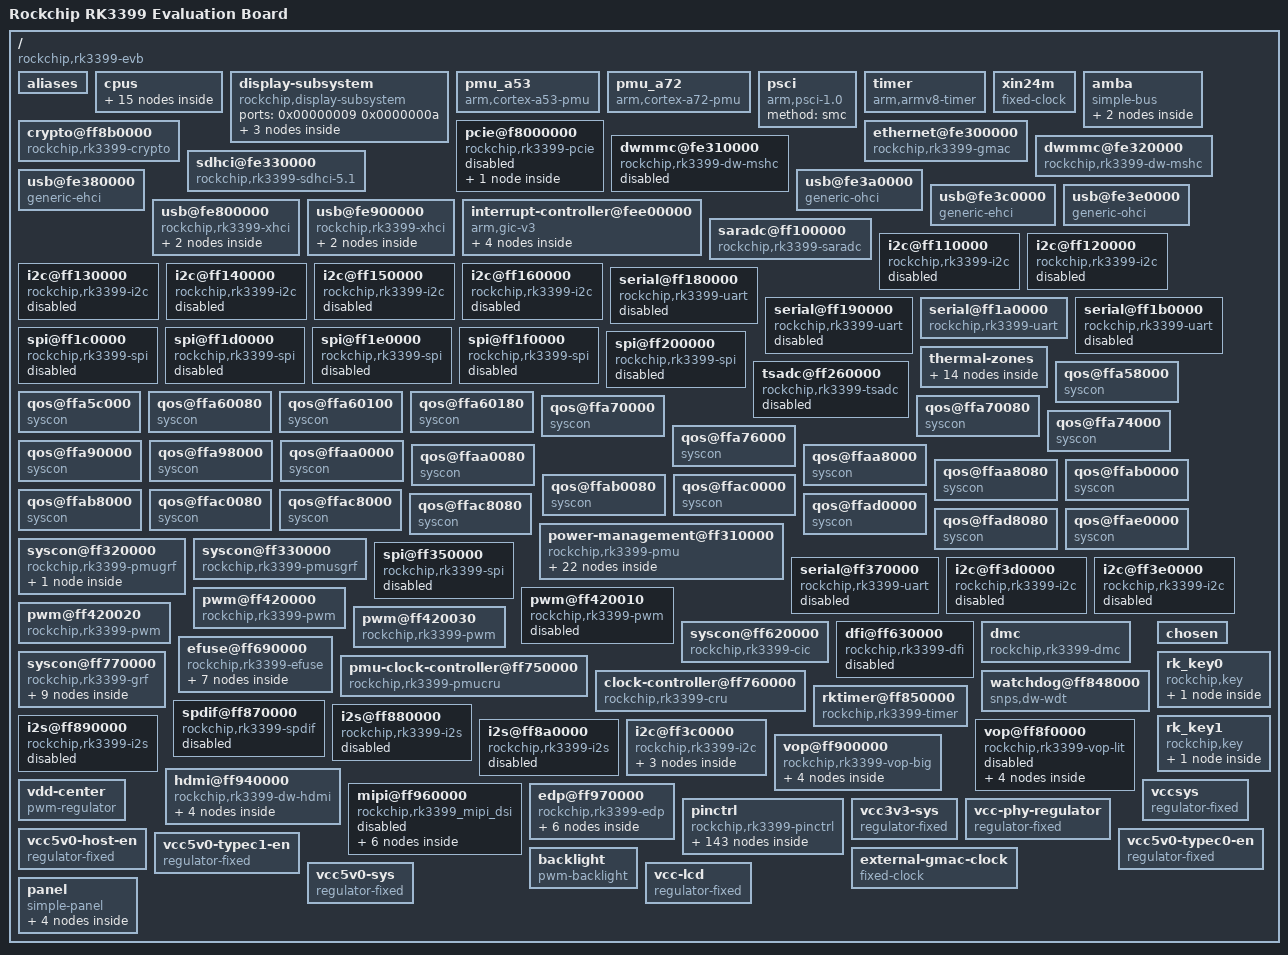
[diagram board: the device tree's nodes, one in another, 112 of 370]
/dts-v1/;
// magic:		0xd00dfeed
// totalsize:		0xc20f (49679)
// off_dt_struct:	0x38
// off_dt_strings:	0xb968
// off_mem_rsvmap:	0x28
// version:		17
// last_comp_version:	16
// boot_cpuid_phys:	0x0
// size_dt_strings:	0x8a7
// size_dt_struct:	0xb930

/ {
    compatible = "rockchip,rk3399-evb", "rockchip,rk3399", "google,rk3399evb-rev2";
    interrupt-parent = <0x00000001>;
    #address-cells = <0x00000002>;
    #size-cells = <0x00000002>;
    model = "Rockchip RK3399 Evaluation Board";
    aliases {
        i2c0 = "/i2c@ff3c0000";
        i2c1 = "/i2c@ff110000";
        i2c2 = "/i2c@ff120000";
        i2c3 = "/i2c@ff130000";
        i2c4 = "/i2c@ff3d0000";
        i2c5 = "/i2c@ff140000";
        i2c6 = "/i2c@ff150000";
        i2c7 = "/i2c@ff160000";
        i2c8 = "/i2c@ff3e0000";
        serial0 = "/serial@ff180000";
        serial1 = "/serial@ff190000";
        serial2 = "/serial@ff1a0000";
        serial3 = "/serial@ff1b0000";
        serial4 = "/serial@ff370000";
        mmc0 = "/sdhci@fe330000";
        mmc1 = "/dwmmc@fe320000";
    };
    cpus {
        #address-cells = <0x00000002>;
        #size-cells = <0x00000000>;
        cpu-map {
            cluster0 {
                core0 {
                    cpu = <0x00000002>;
                };
                core1 {
                    cpu = <0x00000003>;
                };
                core2 {
                    cpu = <0x00000004>;
                };
                core3 {
                    cpu = <0x00000005>;
                };
            };
            cluster1 {
                core0 {
                    cpu = <0x00000006>;
                };
                core1 {
                    cpu = <0x00000007>;
                };
            };
        };
        cpu@0 {
            device_type = "cpu";
            compatible = "arm,cortex-a53", "arm,armv8";
            reg = <0x00000000 0x00000000>;
            enable-method = "psci";
            #cooling-cells = <0x00000002>;
            clocks = <0x00000008 0x00000008>;
            phandle = <0x00000002>;
        };
        cpu@1 {
            device_type = "cpu";
            compatible = "arm,cortex-a53", "arm,armv8";
            reg = <0x00000000 0x00000001>;
            enable-method = "psci";
            clocks = <0x00000008 0x00000008>;
            phandle = <0x00000003>;
        };
        cpu@2 {
            device_type = "cpu";
            compatible = "arm,cortex-a53", "arm,armv8";
            reg = <0x00000000 0x00000002>;
            enable-method = "psci";
            clocks = <0x00000008 0x00000008>;
            phandle = <0x00000004>;
        };
        cpu@3 {
            device_type = "cpu";
            compatible = "arm,cortex-a53", "arm,armv8";
            reg = <0x00000000 0x00000003>;
            enable-method = "psci";
            clocks = <0x00000008 0x00000008>;
            phandle = <0x00000005>;
        };
        cpu@100 {
            device_type = "cpu";
            compatible = "arm,cortex-a72", "arm,armv8";
            reg = <0x00000000 0x00000100>;
            enable-method = "psci";
            #cooling-cells = <0x00000002>;
            clocks = <0x00000008 0x00000009>;
            phandle = <0x00000006>;
        };
        cpu@101 {
            device_type = "cpu";
            compatible = "arm,cortex-a72", "arm,armv8";
            reg = <0x00000000 0x00000101>;
            enable-method = "psci";
            clocks = <0x00000008 0x00000009>;
            phandle = <0x00000007>;
        };
    };
    display-subsystem {
        compatible = "rockchip,display-subsystem";
        ports = <0x00000009 0x0000000a>;
        status = "okay";
        route {
            route-hdmi {
                status = "disabled";
                logo,uboot = "logo.bmp";
                logo,kernel = "logo_kernel.bmp";
                logo,mode = "center";
                charge_logo,mode = "center";
                connect = <0x0000000b>;
            };
            route-edp {
                status = "okay";
                logo,uboot = "logo.bmp";
                logo,kernel = "logo_kernel.bmp";
                logo,mode = "center";
                charge_logo,mode = "center";
                connect = <0x0000000c>;
            };
        };
    };
    pmu_a53 {
        compatible = "arm,cortex-a53-pmu";
        interrupts = <0x00000001 0x00000007 0x00000008 0x0000000d>;
    };
    pmu_a72 {
        compatible = "arm,cortex-a72-pmu";
        interrupts = <0x00000001 0x00000007 0x00000008 0x0000000e>;
    };
    psci {
        compatible = "arm,psci-1.0";
        method = "smc";
    };
    timer {
        compatible = "arm,armv8-timer";
        interrupts = <0x00000001 0x0000000d 0x00000008 0x00000000 0x00000001 0x0000000e 0x00000008 0x00000000 0x00000001 0x0000000b 0x00000008 0x00000000 0x00000001 0x0000000a 0x00000008 0x00000000>;
        arm,no-tick-in-suspend;
    };
    xin24m {
        compatible = "fixed-clock";
        clock-frequency = <0x016e3600>;
        clock-output-names = "xin24m";
        #clock-cells = <0x00000000>;
    };
    amba {
        compatible = "simple-bus";
        #address-cells = <0x00000002>;
        #size-cells = <0x00000002>;
        ranges;
        dma-controller@ff6d0000 {
            compatible = "arm,pl330", "arm,primecell";
            reg = <0x00000000 0xff6d0000 0x00000000 0x00004000>;
            interrupts = <0x00000000 0x00000005 0x00000004 0x00000000 0x00000000 0x00000006 0x00000004 0x00000000>;
            #dma-cells = <0x00000001>;
            clocks = <0x00000008 0x000000d3>;
            clock-names = "apb_pclk";
            phandle = <0x0000006b>;
        };
        dma-controller@ff6e0000 {
            compatible = "arm,pl330", "arm,primecell";
            reg = <0x00000000 0xff6e0000 0x00000000 0x00004000>;
            interrupts = <0x00000000 0x00000007 0x00000004 0x00000000 0x00000000 0x00000008 0x00000004 0x00000000>;
            #dma-cells = <0x00000001>;
            clocks = <0x00000008 0x000000d4>;
            clock-names = "apb_pclk";
        };
    };
    crypto@ff8b0000 {
        compatible = "rockchip,rk3399-crypto";
        reg = <0x00000000 0xff8b0000 0x00000000 0x00010000>;
        clock-names = "sclk_crypto0";
        clocks = <0x00000008 0x00000085 0x00000008 0x00000086>;
        status = "okay";
        u-boot,dm-pre-reloc;
    };
    pcie@f8000000 {
        compatible = "rockchip,rk3399-pcie";
        reg = <0x00000000 0xf8000000 0x00000000 0x02000000 0x00000000 0xfd000000 0x00000000 0x01000000>;
        reg-names = "axi-base", "apb-base";
        #address-cells = <0x00000003>;
        #size-cells = <0x00000002>;
        #interrupt-cells = <0x00000001>;
        aspm-no-l0s;
        bus-range = <0x00000000 0x00000001>;
        clocks = <0x00000008 0x000000c5 0x00000008 0x000000c4 0x00000008 0x00000147 0x00000008 0x000000a0>;
        clock-names = "aclk", "aclk-perf", "hclk", "pm";
        interrupts = <0x00000000 0x00000031 0x00000004 0x00000000 0x00000000 0x00000032 0x00000004 0x00000000 0x00000000 0x00000033 0x00000004 0x00000000>;
        interrupt-names = "sys", "legacy", "client";
        interrupt-map-mask = <0x00000000 0x00000000 0x00000000 0x00000007>;
        interrupt-map = <0x00000000 0x00000000 0x00000000 0x00000001 0x0000000f 0x00000000 0x00000000 0x00000000 0x00000000 0x00000002 0x0000000f 0x00000001 0x00000000 0x00000000 0x00000000 0x00000003 0x0000000f 0x00000002 0x00000000 0x00000000 0x00000000 0x00000004 0x0000000f 0x00000003>;
        linux,pci-domain = <0x00000000>;
        max-link-speed = <0x00000001>;
        msi-map = <0x00000000 0x00000010 0x00000000 0x00001000>;
        phys = <0x00000011>;
        phy-names = "pcie-phy";
        ranges = <0x83000000 0x00000000 0xfa000000 0x00000000 0xfa000000 0x00000000 0x00600000 0x81000000 0x00000000 0xfa600000 0x00000000 0xfa600000 0x00000000 0x00100000>;
        resets = <0x00000008 0x00000082 0x00000008 0x00000083 0x00000008 0x00000084 0x00000008 0x00000085 0x00000008 0x00000086 0x00000008 0x00000081 0x00000008 0x00000080>;
        reset-names = "core", "mgmt", "mgmt-sticky", "pipe", "pm", "pclk", "aclk";
        status = "disabled";
        interrupt-controller {
            interrupt-controller;
            #address-cells = <0x00000000>;
            #interrupt-cells = <0x00000001>;
            phandle = <0x0000000f>;
        };
    };
    ethernet@fe300000 {
        compatible = "rockchip,rk3399-gmac";
        reg = <0x00000000 0xfe300000 0x00000000 0x00010000>;
        interrupts = <0x00000000 0x0000000c 0x00000004 0x00000000>;
        interrupt-names = "macirq";
        clocks = <0x00000008 0x00000069 0x00000008 0x00000067 0x00000008 0x00000068 0x00000008 0x00000066 0x00000008 0x0000006a 0x00000008 0x000000d5 0x00000008 0x00000166>;
        clock-names = "stmmaceth", "mac_clk_rx", "mac_clk_tx", "clk_mac_ref", "clk_mac_refout", "aclk_mac", "pclk_mac";
        power-domains = <0x00000012 0x00000016>;
        resets = <0x00000008 0x00000089>;
        reset-names = "stmmaceth";
        rockchip,grf = <0x00000013>;
        status = "okay";
        phy-supply = <0x00000014>;
        phy-mode = "rgmii";
        clock_in_out = "input";
        snps,reset-gpio = <0x00000015 0x0000000f 0x00000001>;
        snps,reset-active-low;
        snps,reset-delays-us = <0x00000000 0x00002710 0x0000c350>;
        assigned-clocks = <0x00000008 0x000000a6>;
        assigned-clock-parents = <0x00000016>;
        pinctrl-names = "default";
        pinctrl-0 = <0x00000017>;
        tx_delay = <0x00000028>;
        rx_delay = <0x00000011>;
    };
    dwmmc@fe310000 {
        compatible = "rockchip,rk3399-dw-mshc", "rockchip,rk3288-dw-mshc";
        reg = <0x00000000 0xfe310000 0x00000000 0x00004000>;
        interrupts = <0x00000000 0x00000040 0x00000004 0x00000000>;
        max-frequency = <0x08f0d180>;
        clocks = <0x00000008 0x000001ee 0x00000008 0x0000004d 0x00000008 0x0000009c 0x00000008 0x0000009d>;
        clock-names = "biu", "ciu", "ciu-drive", "ciu-sample";
        fifo-depth = <0x00000100>;
        power-domains = <0x00000012 0x0000001c>;
        resets = <0x00000008 0x00000079>;
        reset-names = "reset";
        status = "disabled";
    };
    dwmmc@fe320000 {
        compatible = "rockchip,rk3399-dw-mshc", "rockchip,rk3288-dw-mshc";
        reg = <0x00000000 0xfe320000 0x00000000 0x00004000>;
        interrupts = <0x00000000 0x00000041 0x00000004 0x00000000>;
        max-frequency = <0x08f0d180>;
        clocks = <0x00000008 0x000001ce 0x00000008 0x0000004c 0x00000008 0x0000009a 0x00000008 0x0000009b>;
        clock-names = "biu", "ciu", "ciu-drive", "ciu-sample";
        fifo-depth = <0x00000100>;
        power-domains = <0x00000012 0x0000001b>;
        resets = <0x00000008 0x0000007a>;
        reset-names = "reset";
        status = "okay";
        u-boot,dm-pre-reloc;
        bus-width = <0x00000004>;
    };
    sdhci@fe330000 {
        compatible = "rockchip,rk3399-sdhci-5.1", "arasan,sdhci-5.1";
        reg = <0x00000000 0xfe330000 0x00000000 0x00010000>;
        interrupts = <0x00000000 0x0000000b 0x00000004 0x00000000>;
        arasan,soc-ctl-syscon = <0x00000013>;
        assigned-clocks = <0x00000008 0x0000004e>;
        assigned-clock-rates = <0x0bebc200>;
        max-frequency = <0x08f0d180>;
        clocks = <0x00000008 0x0000004e 0x00000008 0x000000f0>;
        clock-names = "clk_xin", "clk_ahb";
        clock-output-names = "emmc_cardclock";
        #clock-cells = <0x00000000>;
        phys = <0x00000018>;
        phy-names = "phy_arasan";
        power-domains = <0x00000012 0x00000017>;
        status = "okay";
        u-boot,dm-pre-reloc;
        bus-width = <0x00000008>;
        mmc-hs400-1_8v;
        mmc-hs400-enhanced-strobe;
        non-removable;
        phandle = <0x0000006a>;
    };
    usb@fe380000 {
        compatible = "generic-ehci";
        reg = <0x00000000 0xfe380000 0x00000000 0x00020000>;
        interrupts = <0x00000000 0x0000001a 0x00000004 0x00000000>;
        clocks = <0x00000008 0x000001c8 0x00000008 0x000001c9 0x00000019>;
        clock-names = "usbhost", "arbiter", "utmi";
        phys = <0x0000001a>;
        phy-names = "usb";
        power-domains = <0x00000012 0x0000000e>;
        status = "okay";
    };
    usb@fe3a0000 {
        compatible = "generic-ohci";
        reg = <0x00000000 0xfe3a0000 0x00000000 0x00020000>;
        interrupts = <0x00000000 0x0000001c 0x00000004 0x00000000>;
        clocks = <0x00000008 0x000001c8 0x00000008 0x000001c9 0x00000019>;
        clock-names = "usbhost", "arbiter", "utmi";
        phys = <0x0000001a>;
        phy-names = "usb";
        power-domains = <0x00000012 0x0000000e>;
        status = "okay";
    };
    usb@fe3c0000 {
        compatible = "generic-ehci";
        reg = <0x00000000 0xfe3c0000 0x00000000 0x00020000>;
        interrupts = <0x00000000 0x0000001e 0x00000004 0x00000000>;
        clocks = <0x00000008 0x000001ca 0x00000008 0x000001cb 0x0000001b>;
        clock-names = "usbhost", "arbiter", "utmi";
        phys = <0x0000001c>;
        phy-names = "usb";
        power-domains = <0x00000012 0x0000000e>;
        status = "okay";
    };
    usb@fe3e0000 {
        compatible = "generic-ohci";
        reg = <0x00000000 0xfe3e0000 0x00000000 0x00020000>;
        interrupts = <0x00000000 0x00000020 0x00000004 0x00000000>;
        clocks = <0x00000008 0x000001ca 0x00000008 0x000001cb 0x0000001b>;
        clock-names = "usbhost", "arbiter", "utmi";
        phys = <0x0000001c>;
        phy-names = "usb";
        power-domains = <0x00000012 0x0000000e>;
        status = "okay";
    };
    usb@fe800000 {
        compatible = "rockchip,rk3399-xhci";
        reg = <0x00000000 0xfe800000 0x00000000 0x00100000>;
        status = "okay";
        snps,dis-enblslpm-quirk;
        snps,phyif-utmi-bits = <0x00000010>;
        snps,dis-u2-freeclk-exists-quirk;
        snps,dis-u2-susphy-quirk;
        #address-cells = <0x00000002>;
        #size-cells = <0x00000002>;
        u-boot,dm-pre-reloc;
        vbus-supply = <0x0000001d>;
        hub {
            compatible = "usb-hub";
            usb,device-class = <0x00000009>;
        };
        typec_phy0 {
            compatible = "rockchip,rk3399-usb3-phy";
            reg = <0x00000000 0xff7c0000 0x00000000 0x00040000>;
        };
    };
    usb@fe900000 {
        compatible = "rockchip,rk3399-xhci";
        reg = <0x00000000 0xfe900000 0x00000000 0x00100000>;
        status = "okay";
        snps,dis-enblslpm-quirk;
        snps,phyif-utmi-bits = <0x00000010>;
        snps,dis-u2-freeclk-exists-quirk;
        snps,dis-u2-susphy-quirk;
        #address-cells = <0x00000002>;
        #size-cells = <0x00000002>;
        u-boot,dm-pre-reloc;
        vbus-supply = <0x0000001e>;
        hub {
            compatible = "usb-hub";
            usb,device-class = <0x00000009>;
        };
        typec_phy1 {
            compatible = "rockchip,rk3399-usb3-phy";
            reg = <0x00000000 0xff800000 0x00000000 0x00040000>;
        };
    };
    interrupt-controller@fee00000 {
        compatible = "arm,gic-v3";
        #interrupt-cells = <0x00000004>;
        #address-cells = <0x00000002>;
        #size-cells = <0x00000002>;
        ranges;
        interrupt-controller;
        reg = <0x00000000 0xfee00000 0x00000000 0x00010000 0x00000000 0xfef00000 0x00000000 0x000c0000 0x00000000 0xfff00000 0x00000000 0x00010000 0x00000000 0xfff10000 0x00000000 0x00010000 0x00000000 0xfff20000 0x00000000 0x00010000>;
        interrupts = <0x00000001 0x00000009 0x00000004 0x00000000>;
        phandle = <0x00000001>;
        interrupt-controller@fee20000 {
            compatible = "arm,gic-v3-its";
            msi-controller;
            reg = <0x00000000 0xfee20000 0x00000000 0x00020000>;
            phandle = <0x00000010>;
        };
        ppi-partitions {
            interrupt-partition-0 {
                affinity = <0x00000002 0x00000003 0x00000004 0x00000005>;
                phandle = <0x0000000d>;
            };
            interrupt-partition-1 {
                affinity = <0x00000006 0x00000007>;
                phandle = <0x0000000e>;
            };
        };
    };
    saradc@ff100000 {
        compatible = "rockchip,rk3399-saradc";
        reg = <0x00000000 0xff100000 0x00000000 0x00000100>;
        interrupts = <0x00000000 0x0000003e 0x00000004 0x00000000>;
        #io-channel-cells = <0x00000001>;
        clocks = <0x00000008 0x00000050 0x00000008 0x00000165>;
        clock-names = "saradc", "apb_pclk";
        resets = <0x00000008 0x000000d4>;
        reset-names = "saradc-apb";
        status = "okay";
        u-boot,dm-pre-reloc;
        phandle = <0x00000086>;
    };
    i2c@ff110000 {
        compatible = "rockchip,rk3399-i2c";
        reg = <0x00000000 0xff110000 0x00000000 0x00001000>;
        assigned-clocks = <0x00000008 0x00000041>;
        assigned-clock-rates = <0x0bebc200>;
        clocks = <0x00000008 0x00000041 0x00000008 0x00000155>;
        clock-names = "i2c", "pclk";
        interrupts = <0x00000000 0x0000003b 0x00000004 0x00000000>;
        pinctrl-names = "default";
        pinctrl-0 = <0x0000001f>;
        #address-cells = <0x00000001>;
        #size-cells = <0x00000000>;
        status = "disabled";
    };
    i2c@ff120000 {
        compatible = "rockchip,rk3399-i2c";
        reg = <0x00000000 0xff120000 0x00000000 0x00001000>;
        assigned-clocks = <0x00000008 0x00000042>;
        assigned-clock-rates = <0x0bebc200>;
        clocks = <0x00000008 0x00000042 0x00000008 0x00000156>;
        clock-names = "i2c", "pclk";
        interrupts = <0x00000000 0x00000023 0x00000004 0x00000000>;
        pinctrl-names = "default";
        pinctrl-0 = <0x00000020>;
        #address-cells = <0x00000001>;
        #size-cells = <0x00000000>;
        status = "disabled";
    };
    i2c@ff130000 {
        compatible = "rockchip,rk3399-i2c";
        reg = <0x00000000 0xff130000 0x00000000 0x00001000>;
        assigned-clocks = <0x00000008 0x00000043>;
        assigned-clock-rates = <0x0bebc200>;
        clocks = <0x00000008 0x00000043 0x00000008 0x00000157>;
        clock-names = "i2c", "pclk";
        interrupts = <0x00000000 0x00000022 0x00000004 0x00000000>;
        pinctrl-names = "default";
        pinctrl-0 = <0x00000021>;
        #address-cells = <0x00000001>;
        #size-cells = <0x00000000>;
        status = "disabled";
    };
    i2c@ff140000 {
        compatible = "rockchip,rk3399-i2c";
        reg = <0x00000000 0xff140000 0x00000000 0x00001000>;
        assigned-clocks = <0x00000008 0x00000044>;
        assigned-clock-rates = <0x0bebc200>;
        clocks = <0x00000008 0x00000044 0x00000008 0x00000158>;
        clock-names = "i2c", "pclk";
        interrupts = <0x00000000 0x00000026 0x00000004 0x00000000>;
        pinctrl-names = "default";
        pinctrl-0 = <0x00000022>;
        #address-cells = <0x00000001>;
        #size-cells = <0x00000000>;
        status = "disabled";
    };
    i2c@ff150000 {
        compatible = "rockchip,rk3399-i2c";
        reg = <0x00000000 0xff150000 0x00000000 0x00001000>;
        assigned-clocks = <0x00000008 0x00000045>;
        assigned-clock-rates = <0x0bebc200>;
        clocks = <0x00000008 0x00000045 0x00000008 0x00000159>;
        clock-names = "i2c", "pclk";
        interrupts = <0x00000000 0x00000025 0x00000004 0x00000000>;
        pinctrl-names = "default";
        pinctrl-0 = <0x00000023>;
        #address-cells = <0x00000001>;
        #size-cells = <0x00000000>;
        status = "disabled";
    };
    i2c@ff160000 {
        compatible = "rockchip,rk3399-i2c";
        reg = <0x00000000 0xff160000 0x00000000 0x00001000>;
        assigned-clocks = <0x00000008 0x00000046>;
        assigned-clock-rates = <0x0bebc200>;
        clocks = <0x00000008 0x00000046 0x00000008 0x0000015a>;
        clock-names = "i2c", "pclk";
        interrupts = <0x00000000 0x00000024 0x00000004 0x00000000>;
        pinctrl-names = "default";
        pinctrl-0 = <0x00000024>;
        #address-cells = <0x00000001>;
        #size-cells = <0x00000000>;
        status = "disabled";
    };
    serial@ff180000 {
        compatible = "rockchip,rk3399-uart", "snps,dw-apb-uart";
        reg = <0x00000000 0xff180000 0x00000000 0x00000100>;
        clocks = <0x00000008 0x00000051 0x00000008 0x00000160>;
        clock-names = "baudclk", "apb_pclk";
        interrupts = <0x00000000 0x00000063 0x00000004 0x00000000>;
        reg-shift = <0x00000002>;
        reg-io-width = <0x00000004>;
        pinctrl-names = "default";
        pinctrl-0 = <0x00000025>;
        status = "disabled";
    };
    serial@ff190000 {
        compatible = "rockchip,rk3399-uart", "snps,dw-apb-uart";
        reg = <0x00000000 0xff190000 0x00000000 0x00000100>;
        clocks = <0x00000008 0x00000052 0x00000008 0x00000161>;
        clock-names = "baudclk", "apb_pclk";
        interrupts = <0x00000000 0x00000062 0x00000004 0x00000000>;
        reg-shift = <0x00000002>;
        reg-io-width = <0x00000004>;
        pinctrl-names = "default";
        pinctrl-0 = <0x00000026>;
        status = "disabled";
    };
    serial@ff1a0000 {
        compatible = "rockchip,rk3399-uart", "snps,dw-apb-uart";
        reg = <0x00000000 0xff1a0000 0x00000000 0x00000100>;
        clocks = <0x00000008 0x00000053 0x00000008 0x00000162>;
        clock-names = "baudclk", "apb_pclk";
        interrupts = <0x00000000 0x00000064 0x00000004 0x00000000>;
        clock-frequency = <0x016e3600>;
        reg-shift = <0x00000002>;
        reg-io-width = <0x00000004>;
        pinctrl-names = "default";
        pinctrl-0 = <0x00000027>;
        status = "okay";
        u-boot,dm-pre-reloc;
    };
    serial@ff1b0000 {
        compatible = "rockchip,rk3399-uart", "snps,dw-apb-uart";
        reg = <0x00000000 0xff1b0000 0x00000000 0x00000100>;
        clocks = <0x00000008 0x00000054 0x00000008 0x00000163>;
        clock-names = "baudclk", "apb_pclk";
        interrupts = <0x00000000 0x00000065 0x00000004 0x00000000>;
        reg-shift = <0x00000002>;
        reg-io-width = <0x00000004>;
        pinctrl-names = "default";
        pinctrl-0 = <0x00000028>;
        status = "disabled";
    };
    spi@ff1c0000 {
        compatible = "rockchip,rk3399-spi", "rockchip,rk3066-spi";
        reg = <0x00000000 0xff1c0000 0x00000000 0x00001000>;
        clocks = <0x00000008 0x00000047 0x00000008 0x0000015b>;
        clock-names = "spiclk", "apb_pclk";
        interrupts = <0x00000000 0x00000044 0x00000004 0x00000000>;
        pinctrl-names = "default";
        pinctrl-0 = <0x00000029 0x0000002a 0x0000002b 0x0000002c>;
        #address-cells = <0x00000001>;
        #size-cells = <0x00000000>;
        status = "disabled";
    };
    spi@ff1d0000 {
        compatible = "rockchip,rk3399-spi", "rockchip,rk3066-spi";
        reg = <0x00000000 0xff1d0000 0x00000000 0x00001000>;
        clocks = <0x00000008 0x00000048 0x00000008 0x0000015c>;
        clock-names = "spiclk", "apb_pclk";
        interrupts = <0x00000000 0x00000035 0x00000004 0x00000000>;
        pinctrl-names = "default";
        pinctrl-0 = <0x0000002d 0x0000002e 0x0000002f 0x00000030>;
        #address-cells = <0x00000001>;
        #size-cells = <0x00000000>;
        status = "disabled";
    };
    spi@ff1e0000 {
        compatible = "rockchip,rk3399-spi", "rockchip,rk3066-spi";
        reg = <0x00000000 0xff1e0000 0x00000000 0x00001000>;
        clocks = <0x00000008 0x00000049 0x00000008 0x0000015d>;
        clock-names = "spiclk", "apb_pclk";
        interrupts = <0x00000000 0x00000034 0x00000004 0x00000000>;
        pinctrl-names = "default";
        pinctrl-0 = <0x00000031 0x00000032 0x00000033 0x00000034>;
        #address-cells = <0x00000001>;
        #size-cells = <0x00000000>;
        status = "disabled";
    };
    spi@ff1f0000 {
        compatible = "rockchip,rk3399-spi", "rockchip,rk3066-spi";
        reg = <0x00000000 0xff1f0000 0x00000000 0x00001000>;
        clocks = <0x00000008 0x0000004a 0x00000008 0x0000015e>;
        clock-names = "spiclk", "apb_pclk";
        interrupts = <0x00000000 0x00000043 0x00000004 0x00000000>;
        pinctrl-names = "default";
        pinctrl-0 = <0x00000035 0x00000036 0x00000037 0x00000038>;
        #address-cells = <0x00000001>;
        #size-cells = <0x00000000>;
        status = "disabled";
    };
    spi@ff200000 {
        compatible = "rockchip,rk3399-spi", "rockchip,rk3066-spi";
        reg = <0x00000000 0xff200000 0x00000000 0x00001000>;
        clocks = <0x00000008 0x0000004b 0x00000008 0x0000015f>;
        clock-names = "spiclk", "apb_pclk";
        interrupts = <0x00000000 0x00000084 0x00000004 0x00000000>;
        pinctrl-names = "default";
        pinctrl-0 = <0x00000039 0x0000003a 0x0000003b 0x0000003c>;
        #address-cells = <0x00000001>;
        #size-cells = <0x00000000>;
        status = "disabled";
    };
    thermal-zones {
        cpu {
            polling-delay-passive = <0x00000064>;
            polling-delay = <0x000003e8>;
            thermal-sensors = <0x0000003d 0x00000000>;
            trips {
                cpu_alert0 {
                    temperature = <0x00011170>;
                    hysteresis = <0x000007d0>;
                    type = "passive";
                    phandle = <0x0000003e>;
                };
                cpu_alert1 {
                    temperature = <0x000124f8>;
                    hysteresis = <0x000007d0>;
                    type = "passive";
                    phandle = <0x0000003f>;
                };
                cpu_crit {
                    temperature = <0x00017318>;
                    hysteresis = <0x000007d0>;
                    type = "critical";
                };
            };
            cooling-maps {
                map0 {
                    trip = <0x0000003e>;
                    cooling-device = <0x00000006 0xffffffff 0xffffffff>;
                };
                map1 {
                    trip = <0x0000003f>;
                    cooling-device = <0x00000002 0xffffffff 0xffffffff 0x00000006 0xffffffff 0xffffffff>;
                };
            };
        };
        gpu {
            polling-delay-passive = <0x00000064>;
            polling-delay = <0x000003e8>;
            thermal-sensors = <0x0000003d 0x00000001>;
            trips {
                gpu_alert0 {
                    temperature = <0x000124f8>;
                    hysteresis = <0x000007d0>;
                    type = "passive";
                    phandle = <0x00000040>;
                };
                gpu_crit {
                    temperature = <0x00017318>;
                    hysteresis = <0x000007d0>;
                    type = "critical";
                };
            };
            cooling-maps {
                map0 {
                    trip = <0x00000040>;
                    cooling-device = <0x00000006 0xffffffff 0xffffffff>;
                };
            };
        };
    };
    tsadc@ff260000 {
        compatible = "rockchip,rk3399-tsadc";
        reg = <0x00000000 0xff260000 0x00000000 0x00000100>;
        interrupts = <0x00000000 0x00000061 0x00000004 0x00000000>;
        assigned-clocks = <0x00000008 0x0000004f>;
        assigned-clock-rates = <0x000b71b0>;
        clocks = <0x00000008 0x0000004f 0x00000008 0x00000164>;
        clock-names = "tsadc", "apb_pclk";
        resets = <0x00000008 0x000000e8>;
        reset-names = "tsadc-apb";
        rockchip,grf = <0x00000013>;
        rockchip,hw-tshut-temp = <0x00017318>;
        pinctrl-names = "init", "default", "sleep";
        pinctrl-0 = <0x00000041>;
        pinctrl-1 = <0x00000042>;
        pinctrl-2 = <0x00000041>;
        #thermal-sensor-cells = <0x00000001>;
        status = "disabled";
        phandle = <0x0000003d>;
    };
    qos@ffa58000 {
        compatible = "syscon";
        reg = <0x00000000 0xffa58000 0x00000000 0x00000020>;
        phandle = <0x0000004a>;
    };
    qos@ffa5c000 {
        compatible = "syscon";
        reg = <0x00000000 0xffa5c000 0x00000000 0x00000020>;
        phandle = <0x0000004b>;
    };
    qos@ffa60080 {
        compatible = "syscon";
        reg = <0x00000000 0xffa60080 0x00000000 0x00000020>;
        phandle = <0x0000004d>;
    };
    qos@ffa60100 {
        compatible = "syscon";
        reg = <0x00000000 0xffa60100 0x00000000 0x00000020>;
        phandle = <0x0000004e>;
    };
    qos@ffa60180 {
        compatible = "syscon";
        reg = <0x00000000 0xffa60180 0x00000000 0x00000020>;
        phandle = <0x0000004f>;
    };
    qos@ffa70000 {
        compatible = "syscon";
        reg = <0x00000000 0xffa70000 0x00000000 0x00000020>;
        phandle = <0x00000052>;
    };
    qos@ffa70080 {
        compatible = "syscon";
        reg = <0x00000000 0xffa70080 0x00000000 0x00000020>;
        phandle = <0x00000053>;
    };
    qos@ffa74000 {
        compatible = "syscon";
        reg = <0x00000000 0xffa74000 0x00000000 0x00000020>;
        phandle = <0x00000050>;
    };
    qos@ffa76000 {
        compatible = "syscon";
        reg = <0x00000000 0xffa76000 0x00000000 0x00000020>;
        phandle = <0x00000051>;
    };
    qos@ffa90000 {
        compatible = "syscon";
        reg = <0x00000000 0xffa90000 0x00000000 0x00000020>;
        phandle = <0x00000054>;
    };
    qos@ffa98000 {
        compatible = "syscon";
        reg = <0x00000000 0xffa98000 0x00000000 0x00000020>;
        phandle = <0x00000043>;
    };
    qos@ffaa0000 {
        compatible = "syscon";
        reg = <0x00000000 0xffaa0000 0x00000000 0x00000020>;
        phandle = <0x00000055>;
    };
    qos@ffaa0080 {
        compatible = "syscon";
        reg = <0x00000000 0xffaa0080 0x00000000 0x00000020>;
        phandle = <0x00000056>;
    };
    qos@ffaa8000 {
        compatible = "syscon";
        reg = <0x00000000 0xffaa8000 0x00000000 0x00000020>;
        phandle = <0x00000057>;
    };
    qos@ffaa8080 {
        compatible = "syscon";
        reg = <0x00000000 0xffaa8080 0x00000000 0x00000020>;
        phandle = <0x00000058>;
    };
    qos@ffab0000 {
        compatible = "syscon";
        reg = <0x00000000 0xffab0000 0x00000000 0x00000020>;
        phandle = <0x00000044>;
    };
    qos@ffab0080 {
        compatible = "syscon";
        reg = <0x00000000 0xffab0080 0x00000000 0x00000020>;
        phandle = <0x00000045>;
    };
    qos@ffab8000 {
        compatible = "syscon";
        reg = <0x00000000 0xffab8000 0x00000000 0x00000020>;
        phandle = <0x00000046>;
    };
    qos@ffac0000 {
        compatible = "syscon";
        reg = <0x00000000 0xffac0000 0x00000000 0x00000020>;
        phandle = <0x00000047>;
    };
    qos@ffac0080 {
        compatible = "syscon";
        reg = <0x00000000 0xffac0080 0x00000000 0x00000020>;
        phandle = <0x00000048>;
    };
    qos@ffac8000 {
        compatible = "syscon";
        reg = <0x00000000 0xffac8000 0x00000000 0x00000020>;
        phandle = <0x00000059>;
    };
    qos@ffac8080 {
        compatible = "syscon";
        reg = <0x00000000 0xffac8080 0x00000000 0x00000020>;
        phandle = <0x0000005a>;
    };
    qos@ffad0000 {
        compatible = "syscon";
        reg = <0x00000000 0xffad0000 0x00000000 0x00000020>;
        phandle = <0x0000005b>;
    };
    qos@ffad8080 {
        compatible = "syscon";
        reg = <0x00000000 0xffad8080 0x00000000 0x00000020>;
        phandle = <0x0000004c>;
    };
    qos@ffae0000 {
        compatible = "syscon";
        reg = <0x00000000 0xffae0000 0x00000000 0x00000020>;
        phandle = <0x00000049>;
    };
    power-management@ff310000 {
        compatible = "rockchip,rk3399-pmu", "syscon", "simple-mfd";
        reg = <0x00000000 0xff310000 0x00000000 0x00001000>;
        u-boot,dm-pre-reloc;
        power-controller {
            compatible = "rockchip,rk3399-power-controller";
            #power-domain-cells = <0x00000001>;
            #address-cells = <0x00000001>;
            #size-cells = <0x00000000>;
            phandle = <0x00000012>;
            pd_iep@34 {
                reg = <0x00000022>;
                clocks = <0x00000008 0x000000e1 0x00000008 0x000001dd>;
                pm_qos = <0x00000043>;
            };
            pd_rga@33 {
                reg = <0x00000021>;
                clocks = <0x00000008 0x000000dc 0x00000008 0x000001e5>;
                pm_qos = <0x00000044 0x00000045>;
            };
            pd_vcodec@31 {
                reg = <0x0000001f>;
                clocks = <0x00000008 0x000000eb 0x00000008 0x000001ea>;
                pm_qos = <0x00000046>;
            };
            pd_vdu@32 {
                reg = <0x00000020>;
                clocks = <0x00000008 0x000000ed 0x00000008 0x000001ec>;
                pm_qos = <0x00000047 0x00000048>;
            };
            pd_gpu@35 {
                reg = <0x00000023>;
                clocks = <0x00000008 0x000000d0>;
                pm_qos = <0x00000049>;
            };
            pd_edp@25 {
                reg = <0x00000019>;
                clocks = <0x00000008 0x0000016c>;
            };
            pd_emmc@23 {
                reg = <0x00000017>;
                clocks = <0x00000008 0x000000f0>;
                pm_qos = <0x0000004a>;
            };
            pd_gmac@22 {
                reg = <0x00000016>;
                clocks = <0x00000008 0x000000d5 0x00000008 0x00000166>;
                pm_qos = <0x0000004b>;
            };
            pd_perihp@14 {
                reg = <0x0000000e>;
                #address-cells = <0x00000001>;
                #size-cells = <0x00000000>;
                clocks = <0x00000008 0x000000c0>;
                pm_qos = <0x0000004c 0x0000004d 0x0000004e 0x0000004f>;
                pd_sd@27 {
                    reg = <0x0000001b>;
                    clocks = <0x00000008 0x000001ce 0x00000008 0x0000004c>;
                    pm_qos = <0x00000050>;
                };
            };
            pd_sdioaudio@28 {
                reg = <0x0000001c>;
                clocks = <0x00000008 0x000001ee>;
                pm_qos = <0x00000051>;
            };
            pd_usb3@24 {
                reg = <0x00000018>;
                clocks = <0x00000008 0x000000f4>;
                pm_qos = <0x00000052 0x00000053>;
            };
            pd_vio@15 {
                reg = <0x0000000f>;
                #address-cells = <0x00000001>;
                #size-cells = <0x00000000>;
                pd_hdcp@21 {
                    reg = <0x00000015>;
                    clocks = <0x00000008 0x000000de 0x00000008 0x000001e7 0x00000008 0x00000172>;
                    pm_qos = <0x00000054>;
                };
                pd_isp0@19 {
                    reg = <0x00000013>;
                    clocks = <0x00000008 0x000000e5 0x00000008 0x000001df>;
                    pm_qos = <0x00000055 0x00000056>;
                };
                pd_isp1@20 {
                    reg = <0x00000014>;
                    clocks = <0x00000008 0x000000e6 0x00000008 0x000001e0>;
                    pm_qos = <0x00000057 0x00000058>;
                };
                pd_tcpc0@RK3399_PD_TCPC0 {
                    reg = <0x00000008>;
                    clocks = <0x00000008 0x0000007e 0x00000008 0x0000007d>;
                };
                pd_tcpc1@RK3399_PD_TCPC1 {
                    reg = <0x00000009>;
                    clocks = <0x00000008 0x00000080 0x00000008 0x0000007f>;
                };
                pd_vo@16 {
                    reg = <0x00000010>;
                    #address-cells = <0x00000001>;
                    #size-cells = <0x00000000>;
                    pd_vopb@17 {
                        reg = <0x00000011>;
                        clocks = <0x00000008 0x000000d9 0x00000008 0x000001d9>;
                        pm_qos = <0x00000059 0x0000005a>;
                    };
                    pd_vopl@18 {
                        reg = <0x00000012>;
                        clocks = <0x00000008 0x000000db 0x00000008 0x000001db>;
                        pm_qos = <0x0000005b>;
                    };
                };
            };
        };
    };
    syscon@ff320000 {
        compatible = "rockchip,rk3399-pmugrf", "syscon", "simple-mfd";
        reg = <0x00000000 0xff320000 0x00000000 0x00001000>;
        #address-cells = <0x00000001>;
        #size-cells = <0x00000001>;
        u-boot,dm-pre-reloc;
        phandle = <0x00000068>;
        io-domains {
            compatible = "rockchip,rk3399-pmu-io-voltage-domain";
            status = "disabled";
        };
    };
    syscon@ff330000 {
        compatible = "rockchip,rk3399-pmusgrf", "syscon";
        reg = <0x00000000 0xff330000 0x00000000 0x0000e3d4>;
        u-boot,dm-pre-reloc;
    };
    spi@ff350000 {
        compatible = "rockchip,rk3399-spi", "rockchip,rk3066-spi";
        reg = <0x00000000 0xff350000 0x00000000 0x00001000>;
        clocks = <0x0000005c 0x00000003 0x0000005c 0x0000001f>;
        clock-names = "spiclk", "apb_pclk";
        interrupts = <0x00000000 0x0000003c 0x00000004 0x00000000>;
        pinctrl-names = "default";
        pinctrl-0 = <0x0000005d 0x0000005e 0x0000005f 0x00000060>;
        #address-cells = <0x00000001>;
        #size-cells = <0x00000000>;
        status = "disabled";
    };
    serial@ff370000 {
        compatible = "rockchip,rk3399-uart", "snps,dw-apb-uart";
        reg = <0x00000000 0xff370000 0x00000000 0x00000100>;
        clocks = <0x0000005c 0x00000006 0x0000005c 0x00000022>;
        clock-names = "baudclk", "apb_pclk";
        interrupts = <0x00000000 0x00000066 0x00000004 0x00000000>;
        reg-shift = <0x00000002>;
        reg-io-width = <0x00000004>;
        pinctrl-names = "default";
        pinctrl-0 = <0x00000061>;
        status = "disabled";
    };
    i2c@ff3d0000 {
        compatible = "rockchip,rk3399-i2c";
        reg = <0x00000000 0xff3d0000 0x00000000 0x00001000>;
        assigned-clocks = <0x0000005c 0x0000000a>;
        assigned-clock-rates = <0x0bebc200>;
        clocks = <0x0000005c 0x0000000a 0x0000005c 0x0000001c>;
        clock-names = "i2c", "pclk";
        interrupts = <0x00000000 0x00000038 0x00000004 0x00000000>;
        pinctrl-names = "default";
        pinctrl-0 = <0x00000062>;
        #address-cells = <0x00000001>;
        #size-cells = <0x00000000>;
        status = "disabled";
    };
    i2c@ff3e0000 {
        compatible = "rockchip,rk3399-i2c";
        reg = <0x00000000 0xff3e0000 0x00000000 0x00001000>;
        assigned-clocks = <0x0000005c 0x0000000b>;
        assigned-clock-rates = <0x0bebc200>;
        clocks = <0x0000005c 0x0000000b 0x0000005c 0x0000001d>;
        clock-names = "i2c", "pclk";
        interrupts = <0x00000000 0x0000003a 0x00000004 0x00000000>;
        pinctrl-names = "default";
        pinctrl-0 = <0x00000063>;
        #address-cells = <0x00000001>;
        #size-cells = <0x00000000>;
        status = "disabled";
    };
    pwm@ff420000 {
        compatible = "rockchip,rk3399-pwm", "rockchip,rk3288-pwm";
        reg = <0x00000000 0xff420000 0x00000000 0x00000010>;
        #pwm-cells = <0x00000003>;
        pinctrl-names = "active";
        pinctrl-0 = <0x00000064>;
        clocks = <0x0000005c 0x0000001e>;
        clock-names = "pwm";
        status = "okay";
        phandle = <0x0000008b>;
    };
    pwm@ff420010 {
        compatible = "rockchip,rk3399-pwm", "rockchip,rk3288-pwm";
        reg = <0x00000000 0xff420010 0x00000000 0x00000010>;
        #pwm-cells = <0x00000003>;
        pinctrl-names = "active";
        pinctrl-0 = <0x00000065>;
        clocks = <0x0000005c 0x0000001e>;
        clock-names = "pwm";
        status = "disabled";
    };
    pwm@ff420020 {
        compatible = "rockchip,rk3399-pwm", "rockchip,rk3288-pwm";
        reg = <0x00000000 0xff420020 0x00000000 0x00000010>;
        #pwm-cells = <0x00000003>;
        pinctrl-names = "active";
        pinctrl-0 = <0x00000066>;
        clocks = <0x0000005c 0x0000001e>;
        clock-names = "pwm";
        status = "okay";
    };
    pwm@ff420030 {
        compatible = "rockchip,rk3399-pwm", "rockchip,rk3288-pwm";
        reg = <0x00000000 0xff420030 0x00000000 0x00000010>;
        #pwm-cells = <0x00000003>;
        pinctrl-names = "active";
        pinctrl-0 = <0x00000067>;
        clocks = <0x0000005c 0x0000001e>;
        clock-names = "pwm";
        status = "okay";
        phandle = <0x00000087>;
    };
    syscon@ff620000 {
        compatible = "rockchip,rk3399-cic", "syscon";
        reg = <0x00000000 0xff620000 0x00000000 0x00000100>;
        u-boot,dm-pre-reloc;
    };
    dfi@ff630000 {
        reg = <0x00000000 0xff630000 0x00000000 0x00004000>;
        compatible = "rockchip,rk3399-dfi";
        rockchip,pmu = <0x00000068>;
        clocks = <0x00000008 0x00000179>;
        clock-names = "pclk_ddr_mon";
        status = "disabled";
        phandle = <0x00000069>;
    };
    dmc {
        compatible = "rockchip,rk3399-dmc";
        devfreq-events = <0x00000069>;
        interrupts = <0x00000000 0x00000001 0x00000004 0x00000000>;
        clocks = <0x00000008 0x000000aa>;
        clock-names = "dmc_clk";
        reg = <0x00000000 0xffa80000 0x00000000 0x00000800 0x00000000 0xffa80800 0x00000000 0x00001800 0x00000000 0xffa82000 0x00000000 0x00002000 0x00000000 0xffa84000 0x00000000 0x00001000 0x00000000 0xffa88000 0x00000000 0x00000800 0x00000000 0xffa88800 0x00000000 0x00001800 0x00000000 0xffa8a000 0x00000000 0x00002000 0x00000000 0xffa8c000 0x00000000 0x00001000>;
        rockchip,sdram-params = <0x00000002 0x0000000a 0x00000003 0x00000002 0x00000002 0x00000000 0x0000000f 0x0000000f 0x0000000f 0x0000000f 0x00000001 0x1d191519 0x14040808 0x00000002 0x00006226 0x00000054 0x00000000 0x00000002 0x0000000a 0x00000003 0x00000002 0x00000002 0x00000000 0x0000000f 0x0000000f 0x0000000f 0x0000000f 0x00000001 0x1d191519 0x14040808 0x00000002 0x00006226 0x00000054 0x00000000 0x00000320 0x00000006 0x00000002 0x0000000d 0x00000001 0x00000700 0x00000000 0x00000000 0x00000000 0x00000000 0x00000050 0x00027100 0x00000320 0x00001f40 0x00000050 0x00027100 0x00000320 0x00001f40 0x00000050 0x00027100 0x00000320 0x01001f40 0x00000000 0x00000101 0x00020100 0x000000a0 0x00000190 0x00000000 0x06180000 0x00061800 0x04000618 0x33080004 0x280f0622 0x22330800 0x00280f06 0x06223308 0x0600280f 0x00000a0a 0x0600dac0 0x0a0a060c 0x0600dac0 0x0a0a060c 0x0600dac0 0x0203000c 0x0f0c0f00 0x040c0f0c 0x14000a0a 0x03030a0a 0x00010003 0x031b1b1b 0x00111111 0x00000000 0x03010000 0x0c2800a8 0x0c2800a8 0x0c2800a8 0x00000000 0x00060006 0x00140006 0x00140014 0x000f0f0f 0x00000000 0x00000000 0x00000000 0x00b00000 0x00b000b0 0x00b000b0 0x000000b0 0x00000000 0x00000000 0x00000000 0x00000000 0x00000000 0x00000000 0x00000301 0x00000001 0x00000000 0x00000000 0x01000000 0x80104002 0x00040003 0x00040005 0x00030000 0x00050004 0x00000004 0x00040003 0x00040005 0x30a00000 0x00001850 0x185030a0 0x30a00000 0x00001850 0x00000000 0x00000000 0x00000000 0x00000000 0x00000000 0x02020200 0x00020202 0x00030200 0x00040700 0x00000302 0x02000407 0x00000003 0x00030f04 0x00070004 0x00000000 0x00000000 0x00000000 0x00000000 0x00000000 0x00000000 0x00000000 0x00010000 0x20040020 0x00200400 0x01000400 0x00000b80 0x00000000 0x00000001 0x00000002 0x0000000e 0x00000000 0x00000000 0x00000000 0x00000000 0x00000000 0x00a00000 0x00c80050 0x00c80000 0x005000a0 0x000000c8 0x00a000c8 0x00c80050 0x00c80000 0x00000000 0x00000000 0x00000000 0x00430000 0x0000001a 0x001a0043 0x00430000 0x0000001a 0x00010001 0x07000001 0x00000707 0x00000000 0x00000000 0x00000000 0x00000000 0x00000000 0x00000000 0x00430000 0x0000001a 0x001a0043 0x00430000 0x0000001a 0x00010001 0x07000001 0x00000707 0x00000000 0x00000000 0x00000000 0x00000000 0x00000000 0x00000000 0x01000000 0x00000000 0x00000000 0x18151100 0x0000000c 0x00000000 0x00000000 0x00000000 0x00000000 0x00000000 0x00000000 0x00000000 0x00000000 0x00000000 0x00000000 0x00000000 0x00000000 0x00000000 0x00032003 0x00480120 0x00000000 0x01200320 0x00000048 0x00032000 0x00480120 0x00000000 0x00280000 0x00280028 0x01010100 0x01000202 0x0a000002 0x01000f0f 0x00000000 0x00000000 0x00010003 0x00000c03 0x00000100 0x00010000 0x01000000 0x00010000 0x00000001 0x00000000 0x00000000 0x00000000 0x00000000 0x00000000 0x00000000 0x00000000 0x00000000 0x00000000 0x00010000 0x03030301 0x01010808 0x03030001 0x0a0a0a03 0x02080808 0x02050103 0x02050103 0x00050103 0x00020202 0x05020500 0x00020502 0x00000000 0x00000000 0x0d000001 0x00010028 0x00010000 0x00000003 0x00000000 0x00000000 0x00000000 0x00000000 0x00000000 0x00000000 0x00000000 0x00000000 0x00010100 0x01000000 0x00000001 0x00000303 0x00000000 0x00000000 0x00000000 0x00000000 0x00000000 0x00000000 0x00000000 0x00000000 0x00000000 0x00000000 0x00000000 0x00000000 0x00000000 0x00000000 0x00000000 0x000556aa 0x000aaaaa 0x000aa955 0x00055555 0x000b3133 0x0004cd33 0x0004cecc 0x000b32cc 0x00010300 0x03000100 0x00000000 0x00000000 0x00000000 0x00000000 0x00000000 0x00000000 0x00000000 0x00000000 0x00ffff00 0x1e1e0000 0x0800001e 0x00001850 0x00000200 0x00000200 0x00000200 0x00000200 0x00001850 0x0000f320 0x1850050a 0x00000200 0x00000200 0x00000200 0x00000200 0x00001850 0x0000f320 0x1850050a 0x00000200 0x00000200 0x00000200 0x00000200 0x00001850 0x0000f320 0x0202050a 0x03030202 0x00000018 0x00000000 0x00000000 0x00001403 0x00000000 0x00000000 0x00000000 0x00030000 0x000e0020 0x000e0020 0x000e0020 0x00000000 0x00000000 0x01000000 0x00070007 0x00050007 0x00000000 0x00000000 0x00000000 0x00000000 0x00000000 0x00000000 0x00000000 0x00000000 0x01000101 0x01010101 0x01000101 0x01000100 0x00010001 0x00010002 0x00020100 0x00000002 0x00000700 0x00000000 0x000030a0 0x00001850 0x000030a0 0x00001850 0x000030a0 0x18501850 0x00000200 0x00000200 0x00000200 0x00000200 0x00001850 0x00000200 0x00000200 0x00000200 0x00000200 0x00001850 0x00000200 0x00000200 0x00000200 0x00000200 0x00010000 0x00000007 0x81000001 0x0f0003f0 0x3fffffff 0x0f0000a0 0x377ff000 0x0f000020 0x377ff000 0x0f000030 0x377ff000 0x0f0000b0 0x377ff000 0x0f000100 0x377ff000 0x0f000110 0x377ff000 0x0f000010 0x377ff000 0x03000101 0x042e2e2e 0x06180006 0x00061800 0x00000018 0x0c2800a8 0x0c2800a8 0x0c2800a8 0x00000500 0x00000000 0x00000000 0x00000000 0x00000000 0x00000000 0x00000000 0x00000000 0x00000000 0x04040000 0x0d000004 0x00000128 0x00000000 0x00030003 0x00000018 0x00000000 0x00000000 0x03060002 0x03010301 0x01080801 0x04020201 0x01080804 0x00000000 0x03030000 0x0a0a0a03 0x00000000 0x00000000 0x00000000 0x00030300 0x00000014 0x00000000 0x01010300 0x00000000 0x00000000 0x01000000 0x00000101 0x55555a5a 0x55555a5a 0x55555a5a 0x55555a5a 0x0a0a0001 0x0505000a 0x00000005 0x00000100 0x00030000 0x17030000 0x000e0020 0x000e0020 0x000e0020 0x00000000 0x00000000 0x00000100 0x140a0000 0x000a030a 0x03000a03 0x010a000a 0x00000100 0x01000000 0x00000000 0x00000100 0x1e1a0000 0x10010204 0x07070705 0x20000202 0x00201000 0x00201000 0x04041000 0x10100100 0x00010110 0x004b004a 0x1a030000 0x0102041e 0x34000000 0x00000000 0x00000000 0x00000000 0x00004300 0x0001001a 0x004d4d07 0x001a0043 0x4d070001 0x0000434d 0x0001001a 0x004d4d07 0x001a0043 0x4d070001 0x0000434d 0x0001001a 0x004d4d07 0x001a0043 0x4d070001 0x0043004d 0x0001001a 0x004d4d07 0x001a0043 0x4d070001 0x0000434d 0x0001001a 0x004d4d07 0x001a0043 0x4d070001 0x0000434d 0x0001001a 0x004d4d07 0x001a0043 0x4d070001 0x0100004d 0x00c800c8 0x060400c8 0x0c060f11 0x2200d890 0x0a0c2005 0x0f11060a 0x00000c06 0x2200d890 0x0a0c2005 0x0f11060a 0x00000c06 0x2200d890 0x0a0c2005 0x0200020a 0x02000200 0x02000200 0x02000200 0x02000200 0x00000000 0x00000000 0x00000000 0x00000000 0x00000000 0x00000000 0x00000000 0x00000000 0x00000000 0x00000000 0x00000000 0x00000000 0x01000300 0x00185000 0x0000f320 0x00001850 0x0000f320 0x00001850 0x0000f320 0x08000000 0x00000100 0x00000000 0x00000000 0x00000000 0x00000000 0x00000002 0x76543210 0x0004c008 0x000000b3 0x00000000 0x00000000 0x00010000 0x01665555 0x00665555 0x00010f00 0x05010200 0x00000003 0x001700c0 0x00cc0101 0x00030066 0x00000000 0x00000000 0x00000000 0x00000000 0x00000000 0x00000000 0x00000000 0x00000000 0x04080000 0x04080400 0x08000000 0x0c00c007 0x00000100 0x00000100 0x55555555 0xaaaaaaaa 0x55555555 0xaaaaaaaa 0x00005555 0x00000000 0x00000000 0x00000000 0x00000000 0x00000000 0x00000000 0x00000000 0x00000000 0x00000000 0x00000000 0x00000000 0x00000000 0x00000000 0x00000000 0x00000000 0x00000000 0x00000000 0x00000000 0x00000000 0x00200000 0x00000000 0x00000000 0x00000000 0x00000000 0x00000000 0x00000000 0x02700270 0x02700270 0x02700270 0x02700270 0x00000270 0x00000000 0x00000000 0x00000000 0x00000000 0x00800000 0x00800080 0x00800080 0x00800080 0x00800080 0x00800080 0x00800080 0x00800080 0x00800080 0x00b30080 0x00000003 0x00000000 0x00020000 0x00000200 0x00000000 0x51315152 0xc0013150 0x020000c0 0x00100001 0x07054208 0x000f0c18 0x01000140 0x00000c20 0x00000000 0x00000000 0x00000000 0x00000000 0x00000000 0x00000000 0x00000000 0x00000000 0x00000000 0x00000000 0x00000000 0x00000000 0x00000000 0x00000000 0x00000000 0x00000000 0x00000000 0x00000000 0x00000000 0x00000000 0x00000000 0x00000000 0x00000000 0x00000000 0x00000000 0x00000000 0x00000000 0x00000000 0x00000000 0x00000000 0x00000000 0x00000000 0x00000000 0x00000000 0x00000000 0x00000000 0x00000000 0x76543210 0x0004c008 0x000000b3 0x00000000 0x00000000 0x00010000 0x01665555 0x00665555 0x00010f00 0x05010200 0x00000003 0x001700c0 0x00cc0101 0x00030066 0x00000000 0x00000000 0x00000000 0x00000000 0x00000000 0x00000000 0x00000000 0x00000000 0x04080000 0x04080400 0x08000000 0x0c00c007 0x00000100 0x00000100 0x55555555 0xaaaaaaaa 0x55555555 0xaaaaaaaa 0x00005555 0x00000000 0x00000000 0x00000000 0x00000000 0x00000000 0x00000000 0x00000000 0x00000000 0x00000000 0x00000000 0x00000000 0x00000000 0x00000000 0x00000000 0x00000000 0x00000000 0x00000000 0x00000000 0x00000000 0x00200000 0x00000000 0x00000000 0x00000000 0x00000000 0x00000000 0x00000000 0x02700270 0x02700270 0x02700270 0x02700270 0x00000270 0x00000000 0x00000000 0x00000000 0x00000000 0x00800000 0x00800080 0x00800080 0x00800080 0x00800080 0x00800080 0x00800080 0x00800080 0x00800080 0x00b30080 0x00000003 0x00000000 0x00020000 0x00000200 0x00000000 0x51315152 0xc0013150 0x020000c0 0x00100001 0x07054208 0x000f0c18 0x01000140 0x00000c20 0x00000000 0x00000000 0x00000000 0x00000000 0x00000000 0x00000000 0x00000000 0x00000000 0x00000000 0x00000000 0x00000000 0x00000000 0x00000000 0x00000000 0x00000000 0x00000000 0x00000000 0x00000000 0x00000000 0x00000000 0x00000000 0x00000000 0x00000000 0x00000000 0x00000000 0x00000000 0x00000000 0x00000000 0x00000000 0x00000000 0x00000000 0x00000000 0x00000000 0x00000000 0x00000000 0x00000000 0x00000000 0x76543210 0x0004c008 0x000000b3 0x00000000 0x00000000 0x00010000 0x01665555 0x00665555 0x00010f00 0x05010200 0x00000003 0x001700c0 0x00cc0101 0x00030066 0x00000000 0x00000000 0x00000000 0x00000000 0x00000000 0x00000000 0x00000000 0x00000000 0x04080000 0x04080400 0x08000000 0x0c00c007 0x00000100 0x00000100 0x55555555 0xaaaaaaaa 0x55555555 0xaaaaaaaa 0x00005555 0x00000000 0x00000000 0x00000000 0x00000000 0x00000000 0x00000000 0x00000000 0x00000000 0x00000000 0x00000000 0x00000000 0x00000000 0x00000000 0x00000000 0x00000000 0x00000000 0x00000000 0x00000000 0x00000000 0x00200000 0x00000000 0x00000000 0x00000000 0x00000000 0x00000000 0x00000000 0x02700270 0x02700270 0x02700270 0x02700270 0x00000270 0x00000000 0x00000000 0x00000000 0x00000000 0x00800000 0x00800080 0x00800080 0x00800080 0x00800080 0x00800080 0x00800080 0x00800080 0x00800080 0x00b30080 0x00000003 0x00000000 0x00020000 0x00000200 0x00000000 0x51315152 0xc0013150 0x020000c0 0x00100001 0x07054208 0x000f0c18 0x01000140 0x00000c20 0x00000000 0x00000000 0x00000000 0x00000000 0x00000000 0x00000000 0x00000000 0x00000000 0x00000000 0x00000000 0x00000000 0x00000000 0x00000000 0x00000000 0x00000000 0x00000000 0x00000000 0x00000000 0x00000000 0x00000000 0x00000000 0x00000000 0x00000000 0x00000000 0x00000000 0x00000000 0x00000000 0x00000000 0x00000000 0x00000000 0x00000000 0x00000000 0x00000000 0x00000000 0x00000000 0x00000000 0x00000000 0x76543210 0x0004c008 0x000000b3 0x00000000 0x00000000 0x00010000 0x01665555 0x00665555 0x00010f00 0x05010200 0x00000003 0x001700c0 0x00cc0101 0x00030066 0x00000000 0x00000000 0x00000000 0x00000000 0x00000000 0x00000000 0x00000000 0x00000000 0x04080000 0x04080400 0x08000000 0x0c00c007 0x00000100 0x00000100 0x55555555 0xaaaaaaaa 0x55555555 0xaaaaaaaa 0x00005555 0x00000000 0x00000000 0x00000000 0x00000000 0x00000000 0x00000000 0x00000000 0x00000000 0x00000000 0x00000000 0x00000000 0x00000000 0x00000000 0x00000000 0x00000000 0x00000000 0x00000000 0x00000000 0x00000000 0x00200000 0x00000000 0x00000000 0x00000000 0x00000000 0x00000000 0x00000000 0x02700270 0x02700270 0x02700270 0x02700270 0x00000270 0x00000000 0x00000000 0x00000000 0x00000000 0x00800000 0x00800080 0x00800080 0x00800080 0x00800080 0x00800080 0x00800080 0x00800080 0x00800080 0x00b30080 0x00000003 0x00000000 0x00020000 0x00000200 0x00000000 0x51315152 0xc0013150 0x020000c0 0x00100001 0x07054208 0x000f0c18 0x01000140 0x00000c20 0x00000000 0x00000000 0x00000000 0x00000000 0x00000000 0x00000000 0x00000000 0x00000000 0x00000000 0x00000000 0x00000000 0x00000000 0x00000000 0x00000000 0x00000000 0x00000000 0x00000000 0x00000000 0x00000000 0x00000000 0x00000000 0x00000000 0x00000000 0x00000000 0x00000000 0x00000000 0x00000000 0x00000000 0x00000000 0x00000000 0x00000000 0x00000000 0x00000000 0x00000000 0x00000000 0x00000000 0x00000000 0x00000000 0x00800000 0x00000000 0x00000000 0x00000000 0x00000000 0x00000000 0x00000001 0x00000000 0x00000000 0x00000000 0x00400320 0x00000040 0x00806420 0x00917531 0x00806420 0x01917531 0x00020003 0x00000000 0x00000000 0x00000000 0x000556aa 0x000aaaaa 0x000aa955 0x00055555 0x000b3133 0x0004cd33 0x0004cecc 0x000b32cc 0x0a418820 0x103f0000 0x0000003f 0x00038055 0x03800380 0x03800380 0x00000380 0x42080010 0x00000003 0x00000000 0x00000000 0x00000000 0x00000000 0x00000000 0x00000000 0x00000000 0x00000000 0x00000000 0x00000000 0x00000000 0x00000000 0x00000000 0x00000000 0x00000000 0x00000000 0x00000000 0x00000000 0x00000000 0x00000000 0x00000000 0x00000000 0x00000000 0x00000000 0x00000000 0x00000000 0x00000000 0x00000000 0x00000000 0x00000000 0x00000000 0x00000000 0x00000000 0x00000000 0x00000000 0x00000000 0x00000000 0x00000000 0x00000000 0x00000000 0x00000000 0x00000000 0x00000000 0x00000000 0x00000000 0x00000000 0x00000000 0x00000000 0x00000000 0x00000000 0x00000000 0x00000000 0x00000000 0x00000000 0x00000000 0x00000000 0x00000000 0x00000000 0x00000000 0x00000000 0x00000000 0x00000000 0x00000000 0x00000000 0x00000000 0x00000000 0x00000000 0x00000000 0x00000000 0x00000000 0x00000000 0x00000000 0x00000000 0x00000000 0x00000000 0x00000000 0x00000000 0x00000000 0x00000000 0x00000000 0x00000000 0x00000000 0x00000000 0x00000000 0x00000000 0x00000000 0x00000000 0x00000000 0x00000000 0x00000000 0x00000000 0x00800000 0x00000000 0x00000000 0x00000000 0x00000000 0x00000000 0x00000001 0x00000000 0x00000000 0x00000000 0x00400320 0x00000040 0x00008eca 0x00009fdb 0x00008eca 0x01009fdb 0x00020003 0x00000000 0x00000000 0x00000000 0x000556aa 0x000aaaaa 0x000aa955 0x00055555 0x000b3133 0x0004cd33 0x0004cecc 0x000b32cc 0x0004a0e6 0x080f0000 0x0000000f 0x00038055 0x03800380 0x03800380 0x00000380 0x42080010 0x00000003 0x00000000 0x00000000 0x00000000 0x00000000 0x00000000 0x00000000 0x00000000 0x00000000 0x00000000 0x00000000 0x00000000 0x00000000 0x00000000 0x00000000 0x00000000 0x00000000 0x00000000 0x00000000 0x00000000 0x00000000 0x00000000 0x00000000 0x00000000 0x00000000 0x00000000 0x00000000 0x00000000 0x00000000 0x00000000 0x00000000 0x00000000 0x00000000 0x00000000 0x00000000 0x00000000 0x00000000 0x00000000 0x00000000 0x00000000 0x00000000 0x00000000 0x00000000 0x00000000 0x00000000 0x00000000 0x00000000 0x00000000 0x00000000 0x00000000 0x00000000 0x00000000 0x00000000 0x00000000 0x00000000 0x00000000 0x00000000 0x00000000 0x00000000 0x00000000 0x00000000 0x00000000 0x00000000 0x00000000 0x00000000 0x00000000 0x00000000 0x00000000 0x00000000 0x00000000 0x00000000 0x00000000 0x00000000 0x00000000 0x00000000 0x00000000 0x00000000 0x00000000 0x00000000 0x00000000 0x00000000 0x00000000 0x00000000 0x00000000 0x00000000 0x00000000 0x00000000 0x00000000 0x00000000 0x00000000 0x00000000 0x00000000 0x00800000 0x00000000 0x00000000 0x00000000 0x00000000 0x00000000 0x00000001 0x00000000 0x00000000 0x00000000 0x00400320 0x00000040 0x00008eca 0x00009fdb 0x00008eca 0x01009fdb 0x00020003 0x00000000 0x00000000 0x00000000 0x000556aa 0x000aaaaa 0x000aa955 0x00055555 0x000b3133 0x0004cd33 0x0004cecc 0x000b32cc 0x1ee6b16a 0x10000000 0x00000000 0x00038055 0x03800380 0x03800380 0x00000380 0x42080010 0x00000003 0x00000000 0x00000000 0x00000000 0x00000000 0x00000000 0x00000000 0x00000000 0x00000000 0x00000000 0x00000000 0x00000000 0x00000000 0x00000000 0x00000000 0x00000000 0x00000000 0x00000000 0x00000000 0x00000000 0x00000000 0x00000000 0x00000000 0x00000000 0x00000000 0x00000000 0x00000000 0x00000000 0x00000000 0x00000000 0x00000000 0x00000000 0x00000000 0x00000000 0x00000000 0x00000000 0x00000000 0x00000000 0x00000000 0x00000000 0x00000000 0x00000000 0x00000000 0x00000000 0x00000000 0x00000000 0x00000000 0x00000000 0x00000000 0x00000000 0x00000000 0x00000000 0x00000000 0x00000000 0x00000000 0x00000000 0x00000000 0x00000000 0x00000000 0x00000000 0x00000000 0x00000000 0x00000000 0x00000000 0x00000000 0x00000000 0x00000000 0x00000000 0x00000000 0x00000000 0x00000000 0x00000000 0x00000000 0x00000000 0x00000000 0x00000000 0x00000000 0x00000000 0x00000000 0x00000000 0x00000000 0x00000000 0x00000000 0x00000000 0x00000000 0x00000000 0x00000000 0x00000000 0x00000000 0x00000000 0x00000000 0x00000001 0x00000000 0x01000005 0x04000f00 0x00020040 0x00020055 0x00000000 0x00000000 0x00000000 0x00000050 0x00000000 0x00010100 0x00000601 0x00000000 0x00006400 0x01221102 0x00000000 0x00051f00 0x051f051f 0x051f051f 0x00030003 0x03000300 0x00000300 0x01221102 0x00000000 0x00000000 0x03020000 0x00000001 0x00000011 0x00000011 0x00000400 0x00000000 0x00000011 0x00000011 0x00004410 0x00004410 0x00004410 0x00004410 0x00004410 0x00000011 0x00004410 0x00000011 0x00004410 0x00000011 0x00004410 0x00000000 0x00000000 0x00000000 0x04000000 0x00000000 0x00000000 0x00000508 0x00000000 0x00000000 0x00000000 0x00000000 0x00000000 0x00000000 0xe4000000 0x00000000 0x00000000 0x01010000 0x00000000>;
        u-boot,dm-pre-reloc;
    };
    efuse@ff690000 {
        compatible = "rockchip,rk3399-efuse";
        reg = <0x00000000 0xff690000 0x00000000 0x00000080>;
        #address-cells = <0x00000001>;
        #size-cells = <0x00000001>;
        clocks = <0x00000008 0x0000017d>;
        clock-names = "pclk_efuse";
        cpu-id@7 {
            reg = <0x00000007 0x00000010>;
        };
        cpu-leakage@17 {
            reg = <0x00000017 0x00000001>;
        };
        gpu-leakage@18 {
            reg = <0x00000018 0x00000001>;
        };
        center-leakage@19 {
            reg = <0x00000019 0x00000001>;
        };
        cpu-leakage@1a {
            reg = <0x0000001a 0x00000001>;
        };
        logic-leakage@1b {
            reg = <0x0000001b 0x00000001>;
        };
        wafer-info@1c {
            reg = <0x0000001c 0x00000001>;
        };
    };
    pmu-clock-controller@ff750000 {
        compatible = "rockchip,rk3399-pmucru";
        reg = <0x00000000 0xff750000 0x00000000 0x00001000>;
        rockchip,grf = <0x00000068>;
        #clock-cells = <0x00000001>;
        #reset-cells = <0x00000001>;
        assigned-clocks = <0x0000005c 0x00000001>;
        assigned-clock-rates = <0x284af100>;
        u-boot,dm-pre-reloc;
        phandle = <0x0000005c>;
    };
    clock-controller@ff760000 {
        compatible = "rockchip,rk3399-cru";
        reg = <0x00000000 0xff760000 0x00000000 0x00001000>;
        rockchip,grf = <0x00000013>;
        #clock-cells = <0x00000001>;
        #reset-cells = <0x00000001>;
        assigned-clocks = <0x00000008 0x00000005 0x00000008 0x00000004 0x00000008 0x00000006 0x00000008 0x000000c0 0x00000008 0x000001c0 0x00000008 0x00000140 0x00000008 0x000000c2 0x00000008 0x000001c1 0x00000008 0x00000142 0x00000008 0x000000c9 0x00000008 0x000001c2 0x00000008 0x00000143>;
        assigned-clock-rates = <0x2367b880 0x2faf0800 0x3b9aca00 0x08f0d180 0x047868c0 0x023c3460 0x05f5e100 0x05f5e100 0x02faf080 0x23c34600 0x05f5e100 0x02faf080>;
        u-boot,dm-pre-reloc;
        phandle = <0x00000008>;
    };
    syscon@ff770000 {
        compatible = "rockchip,rk3399-grf", "syscon", "simple-mfd";
        reg = <0x00000000 0xff770000 0x00000000 0x00010000>;
        #address-cells = <0x00000001>;
        #size-cells = <0x00000001>;
        u-boot,dm-pre-reloc;
        phandle = <0x00000013>;
        io-domains {
            compatible = "rockchip,rk3399-io-voltage-domain";
            status = "disabled";
        };
        usb2-phy@e450 {
            compatible = "rockchip,rk3399-usb2phy";
            reg = <0x0000e450 0x00000010>;
            clocks = <0x00000008 0x0000007b>;
            clock-names = "phyclk";
            #clock-cells = <0x00000000>;
            clock-output-names = "clk_usbphy0_480m";
            status = "okay";
            u-boot,dm-pre-reloc;
            phandle = <0x00000019>;
            host-port {
                #phy-cells = <0x00000000>;
                interrupts = <0x00000000 0x0000001b 0x00000004 0x00000000>;
                interrupt-names = "linestate";
                status = "disabled";
                phandle = <0x0000001a>;
            };
            otg-port {
                #phy-cells = <0x00000000>;
                interrupts = <0x00000000 0x00000067 0x00000004 0x00000000 0x00000000 0x00000068 0x00000004 0x00000000 0x00000000 0x0000006a 0x00000004 0x00000000>;
                interrupt-names = "otg-bvalid", "otg-id", "linestate";
                status = "okay";
                u-boot,dm-pre-reloc;
            };
        };
        usb2-phy@e460 {
            compatible = "rockchip,rk3399-usb2phy";
            reg = <0x0000e460 0x00000010>;
            clocks = <0x00000008 0x0000007c>;
            clock-names = "phyclk";
            #clock-cells = <0x00000000>;
            clock-output-names = "clk_usbphy1_480m";
            status = "disabled";
            phandle = <0x0000001b>;
            host-port {
                #phy-cells = <0x00000000>;
                interrupts = <0x00000000 0x0000001f 0x00000004 0x00000000>;
                interrupt-names = "linestate";
                status = "disabled";
                phandle = <0x0000001c>;
            };
            otg-port {
                #phy-cells = <0x00000000>;
                interrupts = <0x00000000 0x0000006c 0x00000004 0x00000000 0x00000000 0x0000006d 0x00000004 0x00000000 0x00000000 0x0000006f 0x00000004 0x00000000>;
                interrupt-names = "otg-bvalid", "otg-id", "linestate";
                status = "disabled";
            };
        };
        phy@f780 {
            compatible = "rockchip,rk3399-emmc-phy";
            reg = <0x0000f780 0x00000024>;
            clocks = <0x0000006a>;
            clock-names = "emmcclk";
            #phy-cells = <0x00000000>;
            status = "okay";
            u-boot,dm-pre-reloc;
            phandle = <0x00000018>;
        };
        pcie-phy {
            compatible = "rockchip,rk3399-pcie-phy";
            clocks = <0x00000008 0x0000008a>;
            clock-names = "refclk";
            #phy-cells = <0x00000000>;
            resets = <0x00000008 0x00000087>;
            reset-names = "phy";
            status = "disabled";
            phandle = <0x00000011>;
        };
    };
    watchdog@ff848000 {
        compatible = "snps,dw-wdt";
        reg = <0x00000000 0xff848000 0x00000000 0x00000100>;
        clocks = <0x00000008 0x0000017c>;
        interrupts = <0x00000000 0x00000078 0x00000004 0x00000000>;
    };
    rktimer@ff850000 {
        compatible = "rockchip,rk3399-timer";
        reg = <0x00000000 0xff850000 0x00000000 0x00001000>;
        interrupts = <0x00000000 0x00000051 0x00000004 0x00000000>;
        clocks = <0x00000008 0x00000168 0x00000008 0x0000005a>;
        clock-names = "pclk", "timer";
    };
    spdif@ff870000 {
        compatible = "rockchip,rk3399-spdif";
        reg = <0x00000000 0xff870000 0x00000000 0x00001000>;
        interrupts = <0x00000000 0x00000042 0x00000004 0x00000000>;
        dmas = <0x0000006b 0x00000007>;
        dma-names = "tx";
        clock-names = "mclk", "hclk";
        clocks = <0x00000008 0x00000055 0x00000008 0x000001d7>;
        pinctrl-names = "default";
        pinctrl-0 = <0x0000006c>;
        power-domains = <0x00000012 0x0000001c>;
        status = "disabled";
    };
    i2s@ff880000 {
        compatible = "rockchip,rk3399-i2s", "rockchip,rk3066-i2s";
        reg = <0x00000000 0xff880000 0x00000000 0x00001000>;
        rockchip,grf = <0x00000013>;
        interrupts = <0x00000000 0x00000027 0x00000004 0x00000000>;
        dmas = <0x0000006b 0x00000000 0x0000006b 0x00000001>;
        dma-names = "tx", "rx";
        clock-names = "i2s_clk", "i2s_hclk";
        clocks = <0x00000008 0x00000056 0x00000008 0x000001d4>;
        pinctrl-names = "default";
        pinctrl-0 = <0x0000006d>;
        power-domains = <0x00000012 0x0000001c>;
        status = "disabled";
    };
    i2s@ff890000 {
        compatible = "rockchip,rk3399-i2s", "rockchip,rk3066-i2s";
        reg = <0x00000000 0xff890000 0x00000000 0x00001000>;
        interrupts = <0x00000000 0x00000028 0x00000004 0x00000000>;
        dmas = <0x0000006b 0x00000002 0x0000006b 0x00000003>;
        dma-names = "tx", "rx";
        clock-names = "i2s_clk", "i2s_hclk";
        clocks = <0x00000008 0x00000057 0x00000008 0x000001d5>;
        pinctrl-names = "default";
        pinctrl-0 = <0x0000006e>;
        power-domains = <0x00000012 0x0000001c>;
        status = "disabled";
    };
    i2s@ff8a0000 {
        compatible = "rockchip,rk3399-i2s", "rockchip,rk3066-i2s";
        reg = <0x00000000 0xff8a0000 0x00000000 0x00001000>;
        interrupts = <0x00000000 0x00000029 0x00000004 0x00000000>;
        dmas = <0x0000006b 0x00000004 0x0000006b 0x00000005>;
        dma-names = "tx", "rx";
        clock-names = "i2s_clk", "i2s_hclk";
        clocks = <0x00000008 0x00000058 0x00000008 0x000001d6>;
        power-domains = <0x00000012 0x0000001c>;
        status = "disabled";
    };
    i2c@ff3c0000 {
        compatible = "rockchip,rk3399-i2c";
        reg = <0x00000000 0xff3c0000 0x00000000 0x00001000>;
        assigned-clocks = <0x0000005c 0x00000009>;
        assigned-clock-rates = <0x0bebc200>;
        clocks = <0x0000005c 0x00000009 0x0000005c 0x0000001b>;
        clock-names = "i2c", "pclk";
        interrupts = <0x00000000 0x00000039 0x00000004 0x00000000>;
        pinctrl-names = "default";
        pinctrl-0 = <0x0000006f>;
        #address-cells = <0x00000001>;
        #size-cells = <0x00000000>;
        status = "okay";
        clock-frequency = <0x00061a80>;
        i2c-scl-falling-time-ns = <0x00000032>;
        i2c-scl-rising-time-ns = <0x00000064>;
        pmic@1b {
            compatible = "rockchip,rk808";
            clock-output-names = "xin32k", "wifibt_32kin";
            interrupt-parent = <0x00000070>;
            interrupts = <0x00000004 0x00000008>;
            pinctrl-names = "default";
            pinctrl-0 = <0x00000071>;
            reg = <0x0000001b>;
            rockchip,system-power-controller;
            #clock-cells = <0x00000001>;
            status = "okay";
            vcc12-supply = <0x00000072>;
            regulators {
                SWITCH_REG2 {
                    regulator-always-on;
                    regulator-boot-on;
                    regulator-name = "vcc33_lcd";
                };
            };
        };
    };
    vop@ff8f0000 {
        compatible = "rockchip,rk3399-vop-lit";
        reg = <0x00000000 0xff8f0000 0x00000000 0x00003efc>;
        interrupts = <0x00000000 0x00000077 0x00000004 0x00000000>;
        clocks = <0x00000008 0x000000db 0x00000008 0x000000b5 0x00000008 0x000001db>;
        clock-names = "aclk_vop", "dclk_vop", "hclk_vop";
        resets = <0x00000008 0x00000113 0x00000008 0x00000117 0x00000008 0x00000119>;
        reset-names = "axi", "ahb", "dclk";
        status = "disabled";
        port {
            #address-cells = <0x00000001>;
            #size-cells = <0x00000000>;
            phandle = <0x0000000a>;
            endpoint@0 {
                reg = <0x00000000>;
                remote-endpoint = <0x00000073>;
                phandle = <0x0000007d>;
            };
            endpoint@1 {
                reg = <0x00000001>;
                remote-endpoint = <0x00000074>;
                phandle = <0x0000007a>;
            };
            endpoint@2 {
                reg = <0x00000002>;
                remote-endpoint = <0x00000075>;
                phandle = <0x0000007f>;
            };
        };
    };
    vop@ff900000 {
        compatible = "rockchip,rk3399-vop-big";
        reg = <0x00000000 0xff900000 0x00000000 0x00003efc>;
        interrupts = <0x00000000 0x00000076 0x00000004 0x00000000>;
        clocks = <0x00000008 0x000000d9 0x00000008 0x000000b4 0x00000008 0x000001d9>;
        #clock-cells = <0x00000000>;
        clock-names = "aclk_vop", "dclk_vop", "hclk_vop";
        resets = <0x00000008 0x00000112 0x00000008 0x00000116 0x00000008 0x00000118>;
        reset-names = "axi", "ahb", "dclk";
        status = "okay";
        port {
            #address-cells = <0x00000001>;
            #size-cells = <0x00000000>;
            phandle = <0x00000009>;
            endpoint@0 {
                reg = <0x00000000>;
                remote-endpoint = <0x00000076>;
                phandle = <0x0000007c>;
            };
            endpoint@1 {
                reg = <0x00000001>;
                remote-endpoint = <0x00000077>;
                phandle = <0x0000000b>;
            };
            endpoint@2 {
                reg = <0x00000002>;
                remote-endpoint = <0x00000078>;
                phandle = <0x0000000c>;
            };
        };
    };
    hdmi@ff940000 {
        compatible = "rockchip,rk3399-dw-hdmi";
        reg = <0x00000000 0xff940000 0x00000000 0x00020000>;
        reg-io-width = <0x00000004>;
        rockchip,grf = <0x00000013>;
        pinctrl-names = "default";
        pinctrl-0 = <0x00000079>;
        power-domains = <0x00000012 0x00000015>;
        interrupts = <0x00000000 0x00000017 0x00000004 0x00000000>;
        clocks = <0x00000008 0x00000174 0x00000008 0x00000071 0x00000008 0x00000007 0x00000008 0x0000016f>;
        clock-names = "iahb", "isfr", "vpll", "grf";
        status = "okay";
        ports {
            port {
                #address-cells = <0x00000001>;
                #size-cells = <0x00000000>;
                endpoint@0 {
                    reg = <0x00000000>;
                    remote-endpoint = <0x0000000b>;
                    phandle = <0x00000077>;
                };
                endpoint@1 {
                    reg = <0x00000001>;
                    remote-endpoint = <0x0000007a>;
                    phandle = <0x00000074>;
                };
            };
        };
    };
    mipi@ff960000 {
        compatible = "rockchip,rk3399_mipi_dsi";
        reg = <0x00000000 0xff960000 0x00000000 0x00008000>;
        interrupts = <0x00000000 0x0000002d 0x00000004 0x00000000>;
        clocks = <0x00000008 0x00000077 0x00000008 0x00000170 0x00000008 0x000000a3>;
        clock-names = "ref", "pclk", "phy_cfg";
        rockchip,grf = <0x00000013>;
        #address-cells = <0x00000001>;
        #size-cells = <0x00000000>;
        status = "disabled";
        rockchip,panel = <0x0000007b>;
        ports {
            #address-cells = <0x00000001>;
            #size-cells = <0x00000000>;
            reg = <0x00000001>;
            port {
                #address-cells = <0x00000001>;
                #size-cells = <0x00000000>;
                endpoint@0 {
                    reg = <0x00000000>;
                    remote-endpoint = <0x0000007c>;
                    phandle = <0x00000076>;
                };
                endpoint@1 {
                    reg = <0x00000001>;
                    remote-endpoint = <0x0000007d>;
                    phandle = <0x00000073>;
                };
            };
        };
        display-timings {
            timing0 {
                bits-per-pixel = <0x00000018>;
                clock-frequency = <0x09896800>;
                hfront-porch = <0x00000078>;
                hsync-len = <0x00000014>;
                hback-porch = <0x00000015>;
                hactive = <0x000004b0>;
                vfront-porch = <0x00000015>;
                vsync-len = <0x00000003>;
                vback-porch = <0x00000012>;
                vactive = <0x00000780>;
                hsync-active = <0x00000000>;
                vsync-active = <0x00000000>;
                de-active = <0x00000001>;
                pixelclk-active = <0x00000000>;
            };
        };
    };
    edp@ff970000 {
        compatible = "rockchip,rk3399-edp";
        reg = <0x00000000 0xff970000 0x00000000 0x00008000>;
        interrupts = <0x00000000 0x0000000a 0x00000004 0x00000000>;
        clocks = <0x00000008 0x0000016a 0x00000008 0x0000016c>;
        clock-names = "dp", "pclk";
        power-domains = <0x00000012 0x00000019>;
        resets = <0x00000008 0x0000011d>;
        reset-names = "dp";
        rockchip,grf = <0x00000013>;
        status = "okay";
        pinctrl-names = "default";
        pinctrl-0 = <0x0000007e>;
        force-hpd;
        ports {
            #address-cells = <0x00000001>;
            #size-cells = <0x00000000>;
            port@0 {
                reg = <0x00000000>;
                #address-cells = <0x00000001>;
                #size-cells = <0x00000000>;
                endpoint@0 {
                    reg = <0x00000000>;
                    remote-endpoint = <0x0000000c>;
                    status = "okay";
                    phandle = <0x00000078>;
                };
                endpoint@1 {
                    reg = <0x00000001>;
                    remote-endpoint = <0x0000007f>;
                    status = "disabled";
                    phandle = <0x00000075>;
                };
            };
            port@1 {
                reg = <0x00000001>;
                endpoint {
                    remote-endpoint = <0x00000080>;
                    phandle = <0x00000090>;
                };
            };
        };
    };
    pinctrl {
        compatible = "rockchip,rk3399-pinctrl";
        rockchip,grf = <0x00000013>;
        rockchip,pmu = <0x00000068>;
        #address-cells = <0x00000002>;
        #size-cells = <0x00000002>;
        ranges;
        gpio0@ff720000 {
            compatible = "rockchip,gpio-bank";
            reg = <0x00000000 0xff720000 0x00000000 0x00000100>;
            clocks = <0x0000005c 0x00000017>;
            interrupts = <0x00000000 0x0000000e 0x00000004 0x00000000>;
            gpio-controller;
            #gpio-cells = <0x00000002>;
            interrupt-controller;
            #interrupt-cells = <0x00000002>;
            phandle = <0x00000070>;
        };
        gpio1@ff730000 {
            compatible = "rockchip,gpio-bank";
            reg = <0x00000000 0xff730000 0x00000000 0x00000100>;
            clocks = <0x0000005c 0x00000018>;
            interrupts = <0x00000000 0x0000000f 0x00000004 0x00000000>;
            gpio-controller;
            #gpio-cells = <0x00000002>;
            interrupt-controller;
            #interrupt-cells = <0x00000002>;
            phandle = <0x00000089>;
        };
        gpio2@ff780000 {
            compatible = "rockchip,gpio-bank";
            reg = <0x00000000 0xff780000 0x00000000 0x00000100>;
            clocks = <0x00000008 0x00000150>;
            interrupts = <0x00000000 0x00000010 0x00000004 0x00000000>;
            gpio-controller;
            #gpio-cells = <0x00000002>;
            interrupt-controller;
            #interrupt-cells = <0x00000002>;
        };
        gpio3@ff788000 {
            compatible = "rockchip,gpio-bank";
            reg = <0x00000000 0xff788000 0x00000000 0x00000100>;
            clocks = <0x00000008 0x00000151>;
            interrupts = <0x00000000 0x00000011 0x00000004 0x00000000>;
            gpio-controller;
            #gpio-cells = <0x00000002>;
            interrupt-controller;
            #interrupt-cells = <0x00000002>;
            phandle = <0x00000015>;
        };
        gpio4@ff790000 {
            compatible = "rockchip,gpio-bank";
            reg = <0x00000000 0xff790000 0x00000000 0x00000100>;
            clocks = <0x00000008 0x00000152>;
            interrupts = <0x00000000 0x00000012 0x00000004 0x00000000>;
            gpio-controller;
            #gpio-cells = <0x00000002>;
            interrupt-controller;
            #interrupt-cells = <0x00000002>;
            phandle = <0x00000088>;
        };
        pcfg-pull-up {
            bias-pull-up;
            phandle = <0x00000084>;
        };
        pcfg-pull-down {
            bias-pull-down;
            phandle = <0x00000085>;
        };
        pcfg-pull-none {
            bias-disable;
            phandle = <0x00000081>;
        };
        pcfg-pull-none-12ma {
            bias-disable;
            drive-strength = <0x0000000c>;
            phandle = <0x00000083>;
        };
        pcfg-pull-up-8ma {
            bias-pull-up;
            drive-strength = <0x00000008>;
        };
        pcfg-pull-down-4ma {
            bias-pull-down;
            drive-strength = <0x00000004>;
        };
        pcfg-pull-up-2ma {
            bias-pull-up;
            drive-strength = <0x00000002>;
        };
        pcfg-pull-down-12ma {
            bias-pull-down;
            drive-strength = <0x0000000c>;
        };
        pcfg-pull-none-13ma {
            bias-disable;
            drive-strength = <0x0000000d>;
            phandle = <0x00000082>;
        };
        clock {
            clk-32k {
                rockchip,pins = <0x00000000 0x00000000 0x00000002 0x00000081>;
            };
        };
        edp {
            edp-hpd {
                rockchip,pins = <0x00000004 0x00000017 0x00000002 0x00000081>;
                phandle = <0x0000007e>;
            };
        };
        gmac {
            rgmii-pins {
                rockchip,pins = <0x00000003 0x00000011 0x00000001 0x00000082 0x00000003 0x0000000e 0x00000001 0x00000081 0x00000003 0x0000000d 0x00000001 0x00000081 0x00000003 0x0000000c 0x00000001 0x00000082 0x00000003 0x0000000b 0x00000001 0x00000081 0x00000003 0x00000009 0x00000001 0x00000081 0x00000003 0x00000008 0x00000001 0x00000081 0x00000003 0x00000007 0x00000001 0x00000081 0x00000003 0x00000006 0x00000001 0x00000081 0x00000003 0x00000005 0x00000001 0x00000082 0x00000003 0x00000004 0x00000001 0x00000082 0x00000003 0x00000003 0x00000001 0x00000081 0x00000003 0x00000002 0x00000001 0x00000081 0x00000003 0x00000001 0x00000001 0x00000082 0x00000003 0x00000000 0x00000001 0x00000082>;
                phandle = <0x00000017>;
            };
            rmii-pins {
                rockchip,pins = <0x00000003 0x0000000d 0x00000001 0x00000081 0x00000003 0x0000000c 0x00000001 0x00000082 0x00000003 0x0000000b 0x00000001 0x00000081 0x00000003 0x0000000a 0x00000001 0x00000081 0x00000003 0x00000009 0x00000001 0x00000081 0x00000003 0x00000008 0x00000001 0x00000081 0x00000003 0x00000007 0x00000001 0x00000081 0x00000003 0x00000006 0x00000001 0x00000081 0x00000003 0x00000005 0x00000001 0x00000082 0x00000003 0x00000004 0x00000001 0x00000082>;
            };
        };
        i2c0 {
            i2c0-xfer {
                rockchip,pins = <0x00000001 0x0000000f 0x00000002 0x00000081 0x00000001 0x00000010 0x00000002 0x00000081>;
                phandle = <0x0000006f>;
            };
        };
        i2c1 {
            i2c1-xfer {
                rockchip,pins = <0x00000004 0x00000002 0x00000001 0x00000081 0x00000004 0x00000001 0x00000001 0x00000081>;
                phandle = <0x0000001f>;
            };
        };
        i2c2 {
            i2c2-xfer {
                rockchip,pins = <0x00000002 0x00000001 0x00000002 0x00000083 0x00000002 0x00000000 0x00000002 0x00000083>;
                phandle = <0x00000020>;
            };
        };
        i2c3 {
            i2c3-xfer {
                rockchip,pins = <0x00000004 0x00000011 0x00000001 0x00000081 0x00000004 0x00000010 0x00000001 0x00000081>;
                phandle = <0x00000021>;
            };
        };
        i2c4 {
            i2c4-xfer {
                rockchip,pins = <0x00000001 0x0000000c 0x00000001 0x00000081 0x00000001 0x0000000b 0x00000001 0x00000081>;
                phandle = <0x00000062>;
            };
        };
        i2c5 {
            i2c5-xfer {
                rockchip,pins = <0x00000003 0x0000000b 0x00000002 0x00000081 0x00000003 0x0000000a 0x00000002 0x00000081>;
                phandle = <0x00000022>;
            };
        };
        i2c6 {
            i2c6-xfer {
                rockchip,pins = <0x00000002 0x0000000a 0x00000002 0x00000081 0x00000002 0x00000009 0x00000002 0x00000081>;
                phandle = <0x00000023>;
            };
        };
        i2c7 {
            i2c7-xfer {
                rockchip,pins = <0x00000002 0x00000008 0x00000002 0x00000081 0x00000002 0x00000007 0x00000002 0x00000081>;
                phandle = <0x00000024>;
            };
        };
        i2c8 {
            i2c8-xfer {
                rockchip,pins = <0x00000001 0x00000015 0x00000001 0x00000081 0x00000001 0x00000014 0x00000001 0x00000081>;
                phandle = <0x00000063>;
            };
        };
        i2s0 {
            i2s0-8ch-bus {
                rockchip,pins = <0x00000003 0x00000018 0x00000001 0x00000081 0x00000003 0x00000019 0x00000001 0x00000081 0x00000003 0x0000001a 0x00000001 0x00000081 0x00000003 0x0000001b 0x00000001 0x00000081 0x00000003 0x0000001c 0x00000001 0x00000081 0x00000003 0x0000001d 0x00000001 0x00000081 0x00000003 0x0000001e 0x00000001 0x00000081 0x00000003 0x0000001f 0x00000001 0x00000081 0x00000004 0x00000000 0x00000001 0x00000081>;
                phandle = <0x0000006d>;
            };
        };
        i2s1 {
            i2s1-2ch-bus {
                rockchip,pins = <0x00000004 0x00000003 0x00000001 0x00000081 0x00000004 0x00000004 0x00000001 0x00000081 0x00000004 0x00000005 0x00000001 0x00000081 0x00000004 0x00000006 0x00000001 0x00000081 0x00000004 0x00000007 0x00000001 0x00000081>;
                phandle = <0x0000006e>;
            };
        };
        sdio0 {
            sdio0-bus1 {
                rockchip,pins = <0x00000002 0x00000014 0x00000001 0x00000084>;
            };
            sdio0-bus4 {
                rockchip,pins = <0x00000002 0x00000014 0x00000001 0x00000084 0x00000002 0x00000015 0x00000001 0x00000084 0x00000002 0x00000016 0x00000001 0x00000084 0x00000002 0x00000017 0x00000001 0x00000084>;
            };
            sdio0-cmd {
                rockchip,pins = <0x00000002 0x00000018 0x00000001 0x00000084>;
            };
            sdio0-clk {
                rockchip,pins = <0x00000002 0x00000019 0x00000001 0x00000081>;
            };
            sdio0-cd {
                rockchip,pins = <0x00000002 0x0000001a 0x00000001 0x00000084>;
            };
            sdio0-pwr {
                rockchip,pins = <0x00000002 0x0000001b 0x00000001 0x00000084>;
            };
            sdio0-bkpwr {
                rockchip,pins = <0x00000002 0x0000001c 0x00000001 0x00000084>;
            };
            sdio0-wp {
                rockchip,pins = <0x00000000 0x00000003 0x00000001 0x00000084>;
            };
            sdio0-int {
                rockchip,pins = <0x00000000 0x00000004 0x00000001 0x00000084>;
            };
        };
        sdmmc {
            sdmmc-bus1 {
                rockchip,pins = <0x00000004 0x00000008 0x00000001 0x00000084>;
            };
            sdmmc-bus4 {
                rockchip,pins = <0x00000004 0x00000008 0x00000001 0x00000084 0x00000004 0x00000009 0x00000001 0x00000084 0x00000004 0x0000000a 0x00000001 0x00000084 0x00000004 0x0000000b 0x00000001 0x00000084>;
            };
            sdmmc-clk {
                rockchip,pins = <0x00000004 0x0000000c 0x00000001 0x00000081>;
            };
            sdmmc-cmd {
                rockchip,pins = <0x00000004 0x0000000d 0x00000001 0x00000084>;
            };
            sdmcc-cd {
                rockchip,pins = <0x00000000 0x00000007 0x00000001 0x00000084>;
            };
            sdmmc-wp {
                rockchip,pins = <0x00000000 0x00000008 0x00000001 0x00000084>;
            };
        };
        sleep {
            ap-pwroff {
                rockchip,pins = <0x00000001 0x00000005 0x00000001 0x00000081>;
            };
            ddrio-pwroff {
                rockchip,pins = <0x00000000 0x00000001 0x00000001 0x00000081>;
            };
        };
        spdif {
            spdif-bus {
                rockchip,pins = <0x00000004 0x00000015 0x00000001 0x00000081>;
                phandle = <0x0000006c>;
            };
            spdif-bus-1 {
                rockchip,pins = <0x00000003 0x00000010 0x00000003 0x00000081>;
            };
        };
        spi0 {
            spi0-clk {
                rockchip,pins = <0x00000003 0x00000006 0x00000002 0x00000084>;
                phandle = <0x00000029>;
            };
            spi0-cs0 {
                rockchip,pins = <0x00000003 0x00000007 0x00000002 0x00000084>;
                phandle = <0x0000002c>;
            };
            spi0-cs1 {
                rockchip,pins = <0x00000003 0x00000008 0x00000002 0x00000084>;
            };
            spi0-tx {
                rockchip,pins = <0x00000003 0x00000005 0x00000002 0x00000084>;
                phandle = <0x0000002a>;
            };
            spi0-rx {
                rockchip,pins = <0x00000003 0x00000004 0x00000002 0x00000084>;
                phandle = <0x0000002b>;
            };
        };
        spi1 {
            spi1-clk {
                rockchip,pins = <0x00000001 0x00000009 0x00000002 0x00000084>;
                phandle = <0x0000002d>;
            };
            spi1-cs0 {
                rockchip,pins = <0x00000001 0x0000000a 0x00000002 0x00000084>;
                phandle = <0x00000030>;
            };
            spi1-rx {
                rockchip,pins = <0x00000001 0x00000007 0x00000002 0x00000084>;
                phandle = <0x0000002f>;
            };
            spi1-tx {
                rockchip,pins = <0x00000001 0x00000008 0x00000002 0x00000084>;
                phandle = <0x0000002e>;
            };
        };
        spi2 {
            spi2-clk {
                rockchip,pins = <0x00000002 0x0000000b 0x00000001 0x00000084>;
                phandle = <0x00000031>;
            };
            spi2-cs0 {
                rockchip,pins = <0x00000002 0x0000000c 0x00000001 0x00000084>;
                phandle = <0x00000034>;
            };
            spi2-rx {
                rockchip,pins = <0x00000002 0x00000009 0x00000001 0x00000084>;
                phandle = <0x00000033>;
            };
            spi2-tx {
                rockchip,pins = <0x00000002 0x0000000a 0x00000001 0x00000084>;
                phandle = <0x00000032>;
            };
        };
        spi3 {
            spi3-clk {
                rockchip,pins = <0x00000001 0x00000011 0x00000001 0x00000084>;
                phandle = <0x0000005d>;
            };
            spi3-cs0 {
                rockchip,pins = <0x00000001 0x00000012 0x00000001 0x00000084>;
                phandle = <0x00000060>;
            };
            spi3-rx {
                rockchip,pins = <0x00000001 0x0000000f 0x00000001 0x00000084>;
                phandle = <0x0000005f>;
            };
            spi3-tx {
                rockchip,pins = <0x00000001 0x00000010 0x00000001 0x00000084>;
                phandle = <0x0000005e>;
            };
        };
        spi4 {
            spi4-clk {
                rockchip,pins = <0x00000003 0x00000002 0x00000002 0x00000084>;
                phandle = <0x00000035>;
            };
            spi4-cs0 {
                rockchip,pins = <0x00000003 0x00000003 0x00000002 0x00000084>;
                phandle = <0x00000038>;
            };
            spi4-rx {
                rockchip,pins = <0x00000003 0x00000000 0x00000002 0x00000084>;
                phandle = <0x00000037>;
            };
            spi4-tx {
                rockchip,pins = <0x00000003 0x00000001 0x00000002 0x00000084>;
                phandle = <0x00000036>;
            };
        };
        spi5 {
            spi5-clk {
                rockchip,pins = <0x00000002 0x00000016 0x00000002 0x00000084>;
                phandle = <0x00000039>;
            };
            spi5-cs0 {
                rockchip,pins = <0x00000002 0x00000017 0x00000002 0x00000084>;
                phandle = <0x0000003c>;
            };
            spi5-rx {
                rockchip,pins = <0x00000002 0x00000014 0x00000002 0x00000084>;
                phandle = <0x0000003b>;
            };
            spi5-tx {
                rockchip,pins = <0x00000002 0x00000015 0x00000002 0x00000084>;
                phandle = <0x0000003a>;
            };
        };
        tsadc {
            otp-gpio {
                rockchip,pins = <0x00000001 0x00000006 0x00000000 0x00000081>;
                phandle = <0x00000041>;
            };
            otp-out {
                rockchip,pins = <0x00000001 0x00000006 0x00000001 0x00000081>;
                phandle = <0x00000042>;
            };
        };
        uart0 {
            uart0-xfer {
                rockchip,pins = <0x00000002 0x00000010 0x00000001 0x00000084 0x00000002 0x00000011 0x00000001 0x00000081>;
                phandle = <0x00000025>;
            };
            uart0-cts {
                rockchip,pins = <0x00000002 0x00000012 0x00000001 0x00000081>;
            };
            uart0-rts {
                rockchip,pins = <0x00000002 0x00000013 0x00000001 0x00000081>;
            };
        };
        uart1 {
            uart1-xfer {
                rockchip,pins = <0x00000003 0x0000000c 0x00000002 0x00000084 0x00000003 0x0000000d 0x00000002 0x00000081>;
                phandle = <0x00000026>;
            };
        };
        uart2a {
            uart2a-xfer {
                rockchip,pins = <0x00000004 0x00000008 0x00000002 0x00000084 0x00000004 0x00000009 0x00000002 0x00000081>;
            };
        };
        uart2b {
            uart2b-xfer {
                rockchip,pins = <0x00000004 0x00000010 0x00000002 0x00000084 0x00000004 0x00000011 0x00000002 0x00000081>;
            };
        };
        uart2c {
            uart2c-xfer {
                rockchip,pins = <0x00000004 0x00000013 0x00000001 0x00000084 0x00000004 0x00000014 0x00000001 0x00000081>;
                phandle = <0x00000027>;
            };
        };
        uart3 {
            uart3-xfer {
                rockchip,pins = <0x00000003 0x0000000e 0x00000002 0x00000084 0x00000003 0x0000000f 0x00000002 0x00000081>;
                phandle = <0x00000028>;
            };
            uart3-cts {
                rockchip,pins = <0x00000003 0x00000012 0x00000002 0x00000081>;
            };
            uart3-rts {
                rockchip,pins = <0x00000003 0x00000013 0x00000002 0x00000081>;
            };
        };
        uart4 {
            uart4-xfer {
                rockchip,pins = <0x00000001 0x00000007 0x00000001 0x00000084 0x00000001 0x00000008 0x00000001 0x00000081>;
                phandle = <0x00000061>;
            };
        };
        uarthdcp {
            uarthdcp-xfer {
                rockchip,pins = <0x00000004 0x00000015 0x00000002 0x00000084 0x00000004 0x00000016 0x00000002 0x00000081>;
            };
        };
        pwm0 {
            pwm0-pin {
                rockchip,pins = <0x00000004 0x00000012 0x00000001 0x00000081>;
                phandle = <0x00000064>;
            };
            vop0-pwm-pin {
                rockchip,pins = <0x00000004 0x00000012 0x00000002 0x00000081>;
            };
        };
        pwm1 {
            pwm1-pin {
                rockchip,pins = <0x00000004 0x00000016 0x00000001 0x00000081>;
                phandle = <0x00000065>;
            };
            vop1-pwm-pin {
                rockchip,pins = <0x00000004 0x00000012 0x00000003 0x00000081>;
            };
        };
        pwm2 {
            pwm2-pin {
                rockchip,pins = <0x00000001 0x00000013 0x00000001 0x00000081>;
                phandle = <0x00000066>;
            };
        };
        pwm3a {
            pwm3a-pin {
                rockchip,pins = <0x00000000 0x00000006 0x00000001 0x00000081>;
                phandle = <0x00000067>;
            };
        };
        pwm3b {
            pwm3b-pin {
                rockchip,pins = <0x00000001 0x0000000e 0x00000001 0x00000081>;
            };
        };
        hdmi {
            hdmi-i2c-xfer {
                rockchip,pins = <0x00000004 0x00000011 0x00000003 0x00000081 0x00000004 0x00000010 0x00000003 0x00000081>;
                phandle = <0x00000079>;
            };
            hdmi-cec {
                rockchip,pins = <0x00000004 0x00000017 0x00000001 0x00000081>;
            };
        };
        pcie {
            pci-clkreqn {
                rockchip,pins = <0x00000002 0x0000001a 0x00000002 0x00000081>;
            };
            pci-clkreqnb {
                rockchip,pins = <0x00000004 0x00000018 0x00000001 0x00000081>;
            };
            pci-clkreqn-cpm {
                rockchip,pins = <0x00000002 0x0000001a 0x00000000 0x00000081>;
            };
            pci-clkreqnb-cpm {
                rockchip,pins = <0x00000004 0x00000018 0x00000000 0x00000081>;
            };
        };
        pmic {
            pmic-int-l {
                rockchip,pins = <0x00000001 0x00000015 0x00000000 0x00000084>;
                phandle = <0x00000071>;
            };
            pmic-dvs2 {
                rockchip,pins = <0x00000001 0x00000012 0x00000000 0x00000085>;
            };
        };
    };
    chosen {
        stdout-path = "/serial@ff1a0000";
        u-boot,spl-boot-order = "/sdhci@fe330000", "/dwmmc@fe320000";
    };
    rk_key0 {
        u-boot,dm-pre-reloc;
        compatible = "rockchip,key";
        status = "okay";
        io-channels = <0x00000086 0x00000001>;
        vol-up-key0 {
            u-boot,dm-pre-reloc;
            linux,code = <0x00000073>;
            label = "volume up";
            rockchip,adc_value = <0x00000001>;
        };
    };
    rk_key1 {
        u-boot,dm-pre-reloc;
        compatible = "rockchip,key";
        status = "okay";
        io-channels = <0x00000086 0x00000002>;
        vol-up-key1 {
            u-boot,dm-pre-reloc;
            linux,code = <0x00000073>;
            label = "volume up";
            rockchip,adc_value = <0x0000000a>;
        };
    };
    vdd-center {
        compatible = "pwm-regulator";
        pwms = <0x00000087 0x00000000 0x000061a8 0x00000001>;
        regulator-name = "vdd_center";
        regulator-min-microvolt = <0x000c3500>;
        regulator-max-microvolt = <0x00155cc0>;
        regulator-init-microvolt = <0x000e7ef0>;
        regulator-always-on;
        regulator-boot-on;
        status = "okay";
    };
    vccsys {
        compatible = "regulator-fixed";
        regulator-name = "vccsys";
        regulator-boot-on;
        regulator-always-on;
        phandle = <0x0000008a>;
    };
    vcc3v3-sys {
        compatible = "regulator-fixed";
        regulator-name = "vcc3v3_sys";
        regulator-always-on;
        regulator-boot-on;
        regulator-min-microvolt = <0x00325aa0>;
        regulator-max-microvolt = <0x00325aa0>;
        phandle = <0x00000072>;
    };
    vcc-phy-regulator {
        compatible = "regulator-fixed";
        regulator-name = "vcc_phy";
        regulator-always-on;
        regulator-boot-on;
        phandle = <0x00000014>;
    };
    vcc5v0-host-en {
        compatible = "regulator-fixed";
        regulator-name = "vcc5v0_host";
        gpio = <0x00000088 0x00000019 0x00000000>;
        regulator-min-microvolt = <0x004c4b40>;
        regulator-max-microvolt = <0x004c4b40>;
        regulator-always-on;
        regulator-boot-on;
    };
    vcc5v0-typec0-en {
        compatible = "regulator-fixed";
        regulator-name = "vcc5v0_typec0";
        gpio = <0x00000089 0x00000003 0x00000000>;
        phandle = <0x0000001d>;
    };
    vcc5v0-typec1-en {
        compatible = "regulator-fixed";
        regulator-name = "vcc5v0_typec1";
        gpio = <0x00000089 0x00000004 0x00000000>;
        phandle = <0x0000001e>;
    };
    external-gmac-clock {
        compatible = "fixed-clock";
        clock-frequency = <0x07735940>;
        clock-output-names = "clkin_gmac";
        #clock-cells = <0x00000000>;
        phandle = <0x00000016>;
    };
    backlight {
        compatible = "pwm-backlight";
        power-supply = <0x0000008a>;
        enable-gpios = <0x00000088 0x0000001d 0x00000000>;
        brightness-levels = <0x00000000 0x00000001 0x00000002 0x00000003 0x00000004 0x00000005 0x00000006 0x00000007 0x00000008 0x00000009 0x0000000a 0x0000000b 0x0000000c 0x0000000d 0x0000000e 0x0000000f 0x00000010 0x00000011 0x00000012 0x00000013 0x00000014 0x00000015 0x00000016 0x00000017 0x00000018 0x00000019 0x0000001a 0x0000001b 0x0000001c 0x0000001d 0x0000001e 0x0000001f 0x00000020 0x00000021 0x00000022 0x00000023 0x00000024 0x00000025 0x00000026 0x00000027 0x00000028 0x00000029 0x0000002a 0x0000002b 0x0000002c 0x0000002d 0x0000002e 0x0000002f 0x00000030 0x00000031 0x00000032 0x00000033 0x00000034 0x00000035 0x00000036 0x00000037 0x00000038 0x00000039 0x0000003a 0x0000003b 0x0000003c 0x0000003d 0x0000003e 0x0000003f 0x00000040 0x00000041 0x00000042 0x00000043 0x00000044 0x00000045 0x00000046 0x00000047 0x00000048 0x00000049 0x0000004a 0x0000004b 0x0000004c 0x0000004d 0x0000004e 0x0000004f 0x00000050 0x00000051 0x00000052 0x00000053 0x00000054 0x00000055 0x00000056 0x00000057 0x00000058 0x00000059 0x0000005a 0x0000005b 0x0000005c 0x0000005d 0x0000005e 0x0000005f 0x00000060 0x00000061 0x00000062 0x00000063 0x00000064 0x00000065 0x00000066 0x00000067 0x00000068 0x00000069 0x0000006a 0x0000006b 0x0000006c 0x0000006d 0x0000006e 0x0000006f 0x00000070 0x00000071 0x00000072 0x00000073 0x00000074 0x00000075 0x00000076 0x00000077 0x00000078 0x00000079 0x0000007a 0x0000007b 0x0000007c 0x0000007d 0x0000007e 0x0000007f 0x00000080 0x00000081 0x00000082 0x00000083 0x00000084 0x00000085 0x00000086 0x00000087 0x00000088 0x00000089 0x0000008a 0x0000008b 0x0000008c 0x0000008d 0x0000008e 0x0000008f 0x00000090 0x00000091 0x00000092 0x00000093 0x00000094 0x00000095 0x00000096 0x00000097 0x00000098 0x00000099 0x0000009a 0x0000009b 0x0000009c 0x0000009d 0x0000009e 0x0000009f 0x000000a0 0x000000a1 0x000000a2 0x000000a3 0x000000a4 0x000000a5 0x000000a6 0x000000a7 0x000000a8 0x000000a9 0x000000aa 0x000000ab 0x000000ac 0x000000ad 0x000000ae 0x000000af 0x000000b0 0x000000b1 0x000000b2 0x000000b3 0x000000b4 0x000000b5 0x000000b6 0x000000b7 0x000000b8 0x000000b9 0x000000ba 0x000000bb 0x000000bc 0x000000bd 0x000000be 0x000000bf 0x000000c0 0x000000c1 0x000000c2 0x000000c3 0x000000c4 0x000000c5 0x000000c6 0x000000c7 0x000000c8 0x000000c9 0x000000ca 0x000000cb 0x000000cc 0x000000cd 0x000000ce 0x000000cf 0x000000d0 0x000000d1 0x000000d2 0x000000d3 0x000000d4 0x000000d5 0x000000d6 0x000000d7 0x000000d8 0x000000d9 0x000000da 0x000000db 0x000000dc 0x000000dd 0x000000de 0x000000df 0x000000e0 0x000000e1 0x000000e2 0x000000e3 0x000000e4 0x000000e5 0x000000e6 0x000000e7 0x000000e8 0x000000e9 0x000000ea 0x000000eb 0x000000ec 0x000000ed 0x000000ee 0x000000ef 0x000000f0 0x000000f1 0x000000f2 0x000000f3 0x000000f4 0x000000f5 0x000000f6 0x000000f7 0x000000f8 0x000000f9 0x000000fa 0x000000fb 0x000000fc 0x000000fd 0x000000fe 0x000000ff>;
        default-brightness-level = <0x000000c8>;
        pwms = <0x0000008b 0x00000000 0x000061a8 0x00000000>;
        pinctrl-names = "default";
        pinctrl-0 = <0x00000064>;
        pwm-delay-us = <0x00002710>;
        status = "okay";
        phandle = <0x0000008d>;
    };
    vcc5v0-sys {
        compatible = "regulator-fixed";
        regulator-name = "vcc5v0_sys";
        regulator-always-on;
        regulator-boot-on;
        regulator-min-microvolt = <0x004c4b40>;
        regulator-max-microvolt = <0x004c4b40>;
        phandle = <0x0000008c>;
    };
    vcc-lcd {
        compatible = "regulator-fixed";
        regulator-name = "vcc_lcd";
        gpio = <0x00000088 0x0000001e 0x00000000>;
        startup-delay-us = <0x00004e20>;
        enable-active-high;
        regulator-min-microvolt = <0x00325aa0>;
        regulator-max-microvolt = <0x00325aa0>;
        regulator-boot-on;
        vin-supply = <0x0000008c>;
        phandle = <0x0000008e>;
    };
    panel {
        compatible = "simple-panel";
        backlight = <0x0000008d>;
        power-supply = <0x0000008e>;
        enable-gpios = <0x00000089 0x0000000d 0x00000000>;
        prepare-delay-ms = <0x00000014>;
        enable-delay-ms = <0x00000014>;
        phandle = <0x0000007b>;
        display-timings {
            native-mode = <0x0000008f>;
            timing0 {
                clock-frequency = <0x0bebc200>;
                hactive = <0x00000600>;
                vactive = <0x00000800>;
                hfront-porch = <0x0000000c>;
                hsync-len = <0x00000010>;
                hback-porch = <0x00000030>;
                vfront-porch = <0x00000008>;
                vsync-len = <0x00000004>;
                vback-porch = <0x00000008>;
                hsync-active = <0x00000000>;
                vsync-active = <0x00000000>;
                de-active = <0x00000000>;
                pixelclk-active = <0x00000000>;
                phandle = <0x0000008f>;
            };
        };
        ports {
            endpoint {
                remote-endpoint = <0x00000090>;
                phandle = <0x00000080>;
            };
        };
    };
};
